VERSION ""

NS_ :

BS_:

BU_:
VAL_TABLE_ RadarCfg_OutputType_Valid 1 "valid " 0 "invalid " ;

BO_ 768 VehInfo1: 8 Vector__XXX
 SG_ YawRate_V : 11|1@0+ (1,0) [0|1] "" Vector__XXX
 SG_ YawRate : 23|16@0+ (0.1,-100) [-100|100] "deg/s" Vector__XXX
 SG_ VehSpeed_V : 7|1@0+ (1,0) [0|1] "" Vector__XXX
 SG_ VehSpeed : 6|11@0+ (0.125,0) [0|0] "kph" Vector__XXX

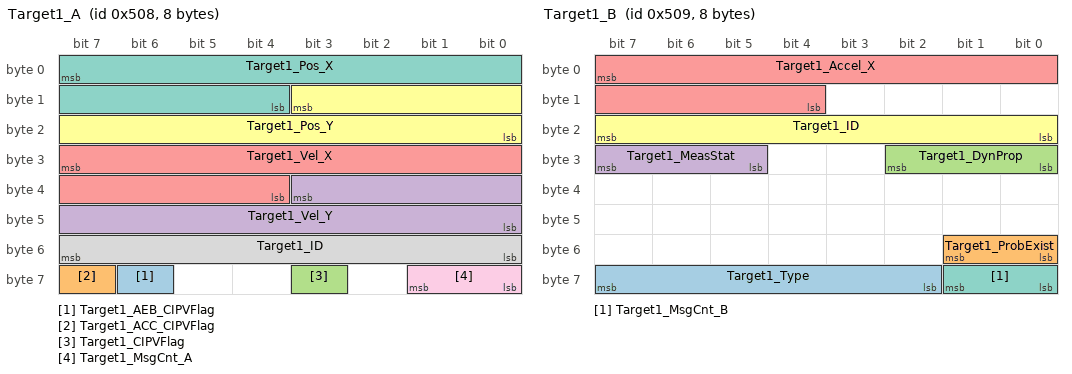
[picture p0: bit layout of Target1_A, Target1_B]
BO_ 1288 Target1_A: 8 Vector__XXX
 SG_ Target1_AEB_CIPVFlag : 62|1@0+ (1,0) [0|1] "" Vector__XXX
 SG_ Target1_ACC_CIPVFlag : 63|1@0+ (1,0) [0|1] "" Vector__XXX
 SG_ Target1_CIPVFlag : 59|1@0+ (1,0) [0|1] "" Vector__XXX
 SG_ Target1_Vel_Y : 35|12@0+ (0.05,-102) [-102|102] "m/s" Vector__XXX
 SG_ Target1_Vel_X : 31|12@0+ (0.05,-102) [-102|102] "m/s" Vector__XXX
 SG_ Target1_Pos_Y : 11|12@0+ (0.125,-128) [-128|127] "m" Vector__XXX
 SG_ Target1_Pos_X : 7|12@0+ (0.125,0) [0|255] "m" Vector__XXX
 SG_ Target1_ID : 55|8@0+ (1,0) [0|255] "" Vector__XXX
 SG_ Target1_MsgCnt_A : 57|2@0+ (1,0) [0|3] "" Vector__XXX

BO_ 1289 Target1_B: 8 Vector__XXX
 SG_ Target1_Type : 63|6@0+ (1,0) [0|4] "" Vector__XXX
 SG_ Target1_ProbExist : 49|2@0+ (1,0) [0|3] "" Vector__XXX
 SG_ Target1_DynProp : 26|3@0+ (1,0) [0|6] "" Vector__XXX
 SG_ Target1_MeasStat : 31|3@0+ (1,0) [0|4] "" Vector__XXX
 SG_ Target1_Accel_X : 7|12@0+ (0.04,-40) [-40|40] "m/s2" Vector__XXX
 SG_ Target1_ID : 23|8@0+ (1,0) [0|255] "" Vector__XXX
 SG_ Target1_MsgCnt_B : 57|2@0+ (1,0) [0|3] "" Vector__XXX

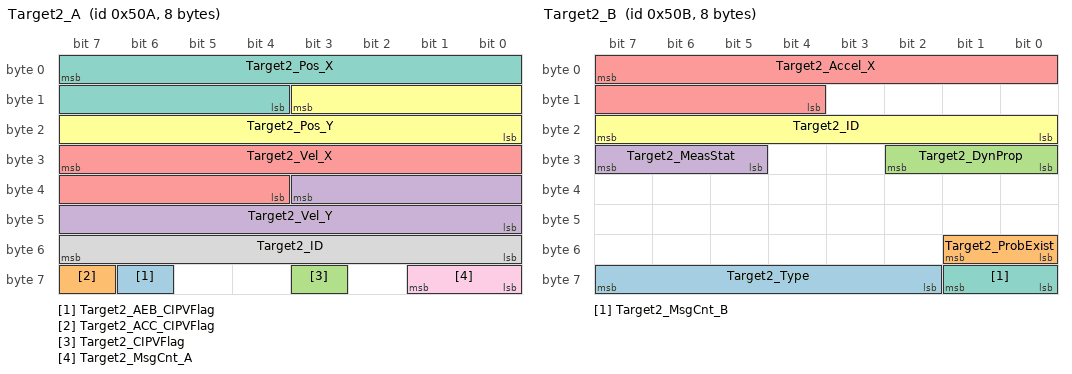
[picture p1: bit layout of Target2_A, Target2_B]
BO_ 1290 Target2_A: 8 Vector__XXX
 SG_ Target2_AEB_CIPVFlag : 62|1@0+ (1,0) [0|1] "" Vector__XXX
 SG_ Target2_ACC_CIPVFlag : 63|1@0+ (1,0) [0|1] "" Vector__XXX
 SG_ Target2_CIPVFlag : 59|1@0+ (1,0) [0|1] "" Vector__XXX
 SG_ Target2_Vel_Y : 35|12@0+ (0.05,-102) [-102|102] "m/s" Vector__XXX
 SG_ Target2_Vel_X : 31|12@0+ (0.05,-102) [-102|102] "m/s" Vector__XXX
 SG_ Target2_Pos_Y : 11|12@0+ (0.125,-128) [-128|127] "m" Vector__XXX
 SG_ Target2_Pos_X : 7|12@0+ (0.125,0) [0|255] "m" Vector__XXX
 SG_ Target2_ID : 55|8@0+ (1,0) [0|255] "" Vector__XXX
 SG_ Target2_MsgCnt_A : 57|2@0+ (1,0) [0|3] "" Vector__XXX

BO_ 1291 Target2_B: 8 Vector__XXX
 SG_ Target2_Type : 63|6@0+ (1,0) [0|4] "" Vector__XXX
 SG_ Target2_ProbExist : 49|2@0+ (1,0) [0|3] "" Vector__XXX
 SG_ Target2_DynProp : 26|3@0+ (1,0) [0|6] "" Vector__XXX
 SG_ Target2_MeasStat : 31|3@0+ (1,0) [0|4] "" Vector__XXX
 SG_ Target2_Accel_X : 7|12@0+ (0.04,-40) [-40|40] "m/s2" Vector__XXX
 SG_ Target2_ID : 23|8@0+ (1,0) [0|255] "" Vector__XXX
 SG_ Target2_MsgCnt_B : 57|2@0+ (1,0) [0|3] "" Vector__XXX

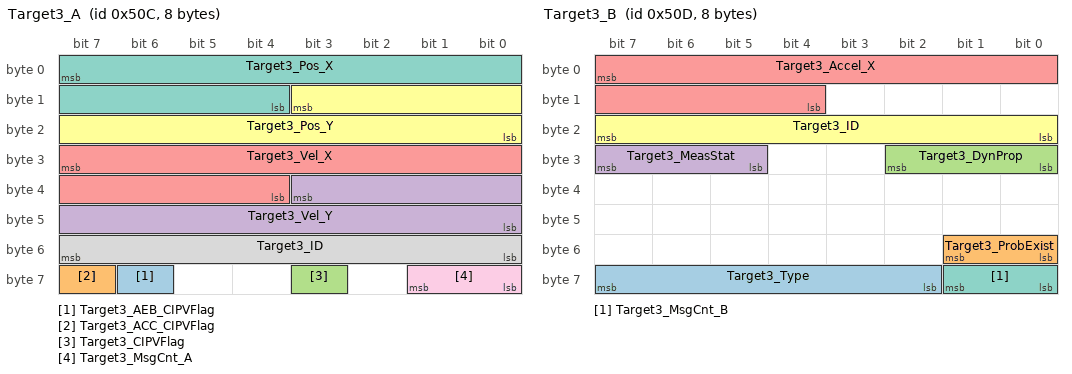
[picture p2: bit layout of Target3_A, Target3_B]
BO_ 1292 Target3_A: 8 Vector__XXX
 SG_ Target3_AEB_CIPVFlag : 62|1@0+ (1,0) [0|1] "" Vector__XXX
 SG_ Target3_ACC_CIPVFlag : 63|1@0+ (1,0) [0|1] "" Vector__XXX
 SG_ Target3_CIPVFlag : 59|1@0+ (1,0) [0|1] "" Vector__XXX
 SG_ Target3_Vel_Y : 35|12@0+ (0.05,-102) [-102|102] "m/s" Vector__XXX
 SG_ Target3_Vel_X : 31|12@0+ (0.05,-102) [-102|102] "m/s" Vector__XXX
 SG_ Target3_Pos_Y : 11|12@0+ (0.125,-128) [-128|127] "m" Vector__XXX
 SG_ Target3_Pos_X : 7|12@0+ (0.125,0) [0|255] "m" Vector__XXX
 SG_ Target3_ID : 55|8@0+ (1,0) [0|255] "" Vector__XXX
 SG_ Target3_MsgCnt_A : 57|2@0+ (1,0) [0|3] "" Vector__XXX

BO_ 1293 Target3_B: 8 Vector__XXX
 SG_ Target3_Type : 63|6@0+ (1,0) [0|4] "" Vector__XXX
 SG_ Target3_ProbExist : 49|2@0+ (1,0) [0|3] "" Vector__XXX
 SG_ Target3_DynProp : 26|3@0+ (1,0) [0|6] "" Vector__XXX
 SG_ Target3_MeasStat : 31|3@0+ (1,0) [0|4] "" Vector__XXX
 SG_ Target3_Accel_X : 7|12@0+ (0.04,-40) [-40|40] "m/s2" Vector__XXX
 SG_ Target3_ID : 23|8@0+ (1,0) [0|255] "" Vector__XXX
 SG_ Target3_MsgCnt_B : 57|2@0+ (1,0) [0|3] "" Vector__XXX

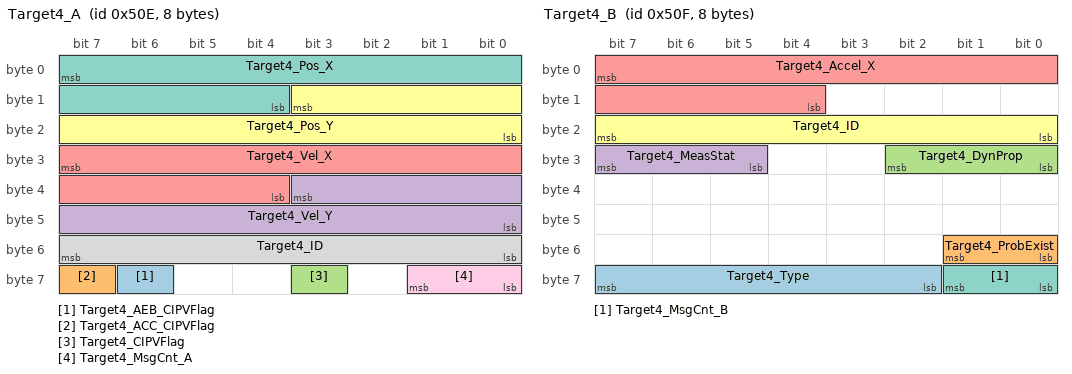
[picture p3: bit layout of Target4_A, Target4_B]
BO_ 1294 Target4_A: 8 Vector__XXX
 SG_ Target4_AEB_CIPVFlag : 62|1@0+ (1,0) [0|1] "" Vector__XXX
 SG_ Target4_ACC_CIPVFlag : 63|1@0+ (1,0) [0|1] "" Vector__XXX
 SG_ Target4_CIPVFlag : 59|1@0+ (1,0) [0|1] "" Vector__XXX
 SG_ Target4_Vel_Y : 35|12@0+ (0.05,-102) [-102|102] "m/s" Vector__XXX
 SG_ Target4_Vel_X : 31|12@0+ (0.05,-102) [-102|102] "m/s" Vector__XXX
 SG_ Target4_Pos_Y : 11|12@0+ (0.125,-128) [-128|127] "m" Vector__XXX
 SG_ Target4_Pos_X : 7|12@0+ (0.125,0) [0|255] "m" Vector__XXX
 SG_ Target4_ID : 55|8@0+ (1,0) [0|255] "" Vector__XXX
 SG_ Target4_MsgCnt_A : 57|2@0+ (1,0) [0|3] "" Vector__XXX

BO_ 1295 Target4_B: 8 Vector__XXX
 SG_ Target4_Type : 63|6@0+ (1,0) [0|4] "" Vector__XXX
 SG_ Target4_ProbExist : 49|2@0+ (1,0) [0|3] "" Vector__XXX
 SG_ Target4_DynProp : 26|3@0+ (1,0) [0|6] "" Vector__XXX
 SG_ Target4_MeasStat : 31|3@0+ (1,0) [0|4] "" Vector__XXX
 SG_ Target4_Accel_X : 7|12@0+ (0.04,-40) [-40|40] "m/s2" Vector__XXX
 SG_ Target4_ID : 23|8@0+ (1,0) [0|255] "" Vector__XXX
 SG_ Target4_MsgCnt_B : 57|2@0+ (1,0) [0|3] "" Vector__XXX

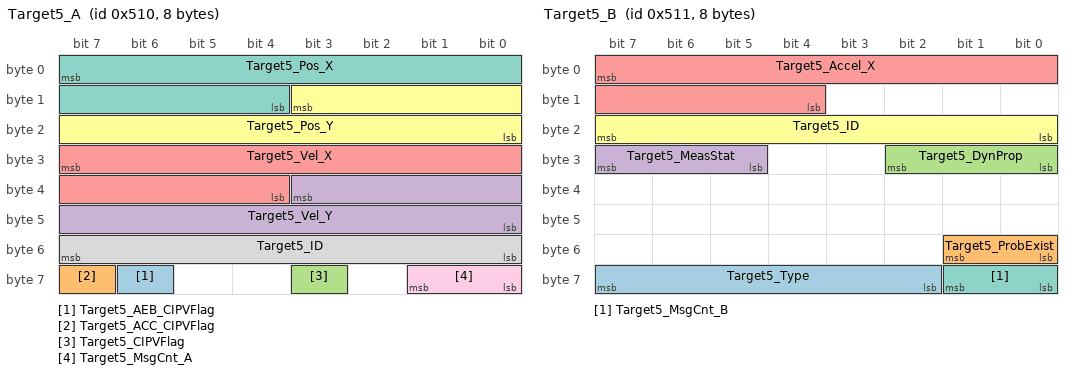
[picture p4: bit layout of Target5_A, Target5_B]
BO_ 1296 Target5_A: 8 Vector__XXX
 SG_ Target5_AEB_CIPVFlag : 62|1@0+ (1,0) [0|1] "" Vector__XXX
 SG_ Target5_ACC_CIPVFlag : 63|1@0+ (1,0) [0|1] "" Vector__XXX
 SG_ Target5_CIPVFlag : 59|1@0+ (1,0) [0|1] "" Vector__XXX
 SG_ Target5_Vel_Y : 35|12@0+ (0.05,-102) [-102|102] "m/s" Vector__XXX
 SG_ Target5_Vel_X : 31|12@0+ (0.05,-102) [-102|102] "m/s" Vector__XXX
 SG_ Target5_Pos_Y : 11|12@0+ (0.125,-128) [-128|127] "m" Vector__XXX
 SG_ Target5_Pos_X : 7|12@0+ (0.125,0) [0|255] "m" Vector__XXX
 SG_ Target5_ID : 55|8@0+ (1,0) [0|255] "" Vector__XXX
 SG_ Target5_MsgCnt_A : 57|2@0+ (1,0) [0|3] "" Vector__XXX

BO_ 1297 Target5_B: 8 Vector__XXX
 SG_ Target5_Type : 63|6@0+ (1,0) [0|4] "" Vector__XXX
 SG_ Target5_ProbExist : 49|2@0+ (1,0) [0|3] "" Vector__XXX
 SG_ Target5_DynProp : 26|3@0+ (1,0) [0|6] "" Vector__XXX
 SG_ Target5_MeasStat : 31|3@0+ (1,0) [0|4] "" Vector__XXX
 SG_ Target5_Accel_X : 7|12@0+ (0.04,-40) [-40|40] "m/s2" Vector__XXX
 SG_ Target5_ID : 23|8@0+ (1,0) [0|255] "" Vector__XXX
 SG_ Target5_MsgCnt_B : 57|2@0+ (1,0) [0|3] "" Vector__XXX

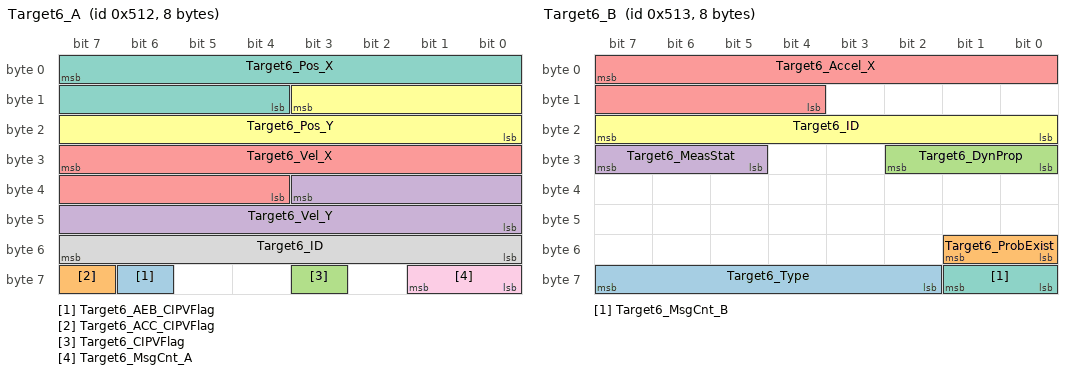
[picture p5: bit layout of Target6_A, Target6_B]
BO_ 1298 Target6_A: 8 Vector__XXX
 SG_ Target6_AEB_CIPVFlag : 62|1@0+ (1,0) [0|1] "" Vector__XXX
 SG_ Target6_ACC_CIPVFlag : 63|1@0+ (1,0) [0|1] "" Vector__XXX
 SG_ Target6_CIPVFlag : 59|1@0+ (1,0) [0|1] "" Vector__XXX
 SG_ Target6_Vel_Y : 35|12@0+ (0.05,-102) [-102|102] "m/s" Vector__XXX
 SG_ Target6_Vel_X : 31|12@0+ (0.05,-102) [-102|102] "m/s" Vector__XXX
 SG_ Target6_Pos_Y : 11|12@0+ (0.125,-128) [-128|127] "m" Vector__XXX
 SG_ Target6_Pos_X : 7|12@0+ (0.125,0) [0|255] "m" Vector__XXX
 SG_ Target6_ID : 55|8@0+ (1,0) [0|255] "" Vector__XXX
 SG_ Target6_MsgCnt_A : 57|2@0+ (1,0) [0|3] "" Vector__XXX

BO_ 1299 Target6_B: 8 Vector__XXX
 SG_ Target6_Type : 63|6@0+ (1,0) [0|4] "" Vector__XXX
 SG_ Target6_ProbExist : 49|2@0+ (1,0) [0|3] "" Vector__XXX
 SG_ Target6_DynProp : 26|3@0+ (1,0) [0|6] "" Vector__XXX
 SG_ Target6_MeasStat : 31|3@0+ (1,0) [0|4] "" Vector__XXX
 SG_ Target6_Accel_X : 7|12@0+ (0.04,-40) [-40|40] "m/s2" Vector__XXX
 SG_ Target6_ID : 23|8@0+ (1,0) [0|255] "" Vector__XXX
 SG_ Target6_MsgCnt_B : 57|2@0+ (1,0) [0|3] "" Vector__XXX

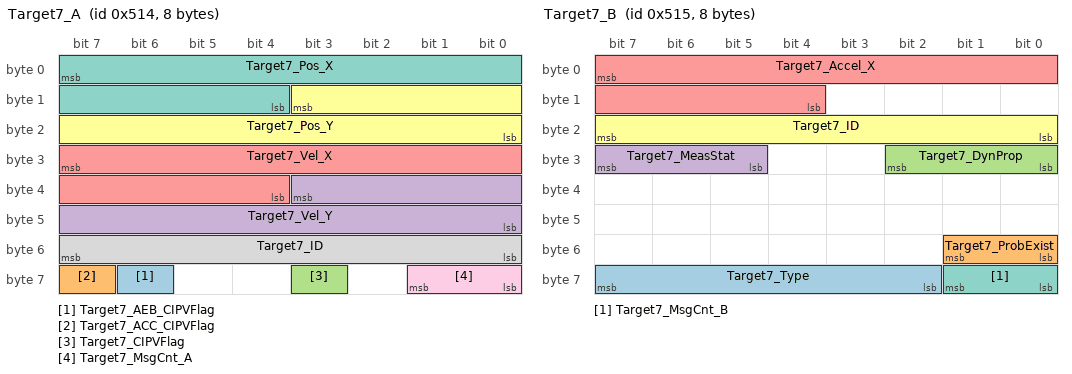
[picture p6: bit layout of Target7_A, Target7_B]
BO_ 1300 Target7_A: 8 Vector__XXX
 SG_ Target7_AEB_CIPVFlag : 62|1@0+ (1,0) [0|1] "" Vector__XXX
 SG_ Target7_ACC_CIPVFlag : 63|1@0+ (1,0) [0|1] "" Vector__XXX
 SG_ Target7_CIPVFlag : 59|1@0+ (1,0) [0|1] "" Vector__XXX
 SG_ Target7_Vel_Y : 35|12@0+ (0.05,-102) [-102|102] "m/s" Vector__XXX
 SG_ Target7_Vel_X : 31|12@0+ (0.05,-102) [-102|102] "m/s" Vector__XXX
 SG_ Target7_Pos_Y : 11|12@0+ (0.125,-128) [-128|127] "m" Vector__XXX
 SG_ Target7_Pos_X : 7|12@0+ (0.125,0) [0|255] "m" Vector__XXX
 SG_ Target7_ID : 55|8@0+ (1,0) [0|255] "" Vector__XXX
 SG_ Target7_MsgCnt_A : 57|2@0+ (1,0) [0|3] "" Vector__XXX

BO_ 1301 Target7_B: 8 Vector__XXX
 SG_ Target7_Type : 63|6@0+ (1,0) [0|4] "" Vector__XXX
 SG_ Target7_ProbExist : 49|2@0+ (1,0) [0|3] "" Vector__XXX
 SG_ Target7_DynProp : 26|3@0+ (1,0) [0|6] "" Vector__XXX
 SG_ Target7_MeasStat : 31|3@0+ (1,0) [0|4] "" Vector__XXX
 SG_ Target7_Accel_X : 7|12@0+ (0.04,-40) [-40|40] "m/s2" Vector__XXX
 SG_ Target7_ID : 23|8@0+ (1,0) [0|255] "" Vector__XXX
 SG_ Target7_MsgCnt_B : 57|2@0+ (1,0) [0|3] "" Vector__XXX

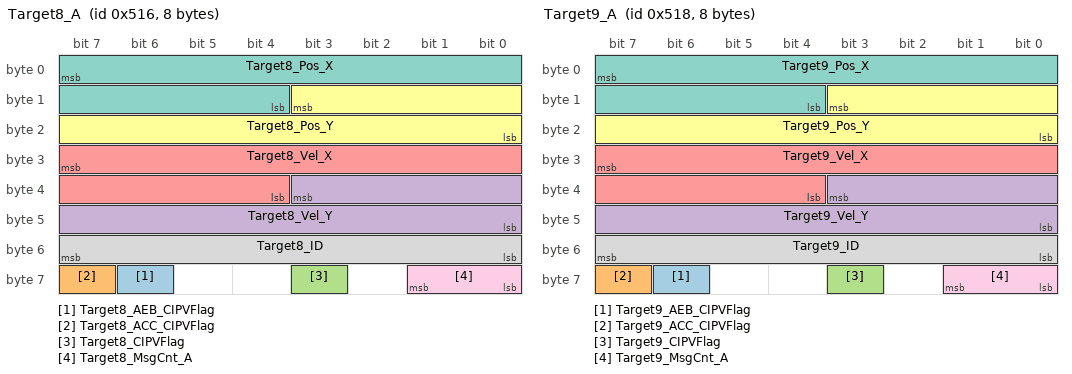
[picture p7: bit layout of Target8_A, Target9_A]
BO_ 1302 Target8_A: 8 Vector__XXX
 SG_ Target8_AEB_CIPVFlag : 62|1@0+ (1,0) [0|1] "" Vector__XXX
 SG_ Target8_ACC_CIPVFlag : 63|1@0+ (1,0) [0|1] "" Vector__XXX
 SG_ Target8_CIPVFlag : 59|1@0+ (1,0) [0|1] "" Vector__XXX
 SG_ Target8_Vel_Y : 35|12@0+ (0.05,-102) [-102|102] "m/s" Vector__XXX
 SG_ Target8_Vel_X : 31|12@0+ (0.05,-102) [-102|102] "m/s" Vector__XXX
 SG_ Target8_Pos_Y : 11|12@0+ (0.125,-128) [-128|127] "m" Vector__XXX
 SG_ Target8_Pos_X : 7|12@0+ (0.125,0) [0|255] "m" Vector__XXX
 SG_ Target8_ID : 55|8@0+ (1,0) [0|255] "" Vector__XXX
 SG_ Target8_MsgCnt_A : 57|2@0+ (1,0) [0|3] "" Vector__XXX

BO_ 1303 Target8_B: 8 Vector__XXX
 SG_ Target8_Type : 63|6@0+ (1,0) [0|4] "" Vector__XXX
 SG_ Target8_ProbExist : 49|2@0+ (1,0) [0|3] "" Vector__XXX
 SG_ Target8_DynProp : 26|3@0+ (1,0) [0|6] "" Vector__XXX
 SG_ Target8_MeasStat : 31|3@0+ (1,0) [0|4] "" Vector__XXX
 SG_ Target8_Accel_X : 7|12@0+ (0.04,-40) [-40|40] "m/s2" Vector__XXX
 SG_ Target8_ID : 23|8@0+ (1,0) [0|255] "" Vector__XXX
 SG_ Target8_MsgCnt_B : 57|2@0+ (1,0) [0|3] "" Vector__XXX

BO_ 1304 Target9_A: 8 Vector__XXX
 SG_ Target9_AEB_CIPVFlag : 62|1@0+ (1,0) [0|1] "" Vector__XXX
 SG_ Target9_ACC_CIPVFlag : 63|1@0+ (1,0) [0|1] "" Vector__XXX
 SG_ Target9_CIPVFlag : 59|1@0+ (1,0) [0|1] "" Vector__XXX
 SG_ Target9_Vel_Y : 35|12@0+ (0.05,-102) [-102|102] "m/s" Vector__XXX
 SG_ Target9_Vel_X : 31|12@0+ (0.05,-102) [-102|102] "m/s" Vector__XXX
 SG_ Target9_Pos_Y : 11|12@0+ (0.125,-128) [-128|127] "m" Vector__XXX
 SG_ Target9_Pos_X : 7|12@0+ (0.125,0) [0|255] "m" Vector__XXX
 SG_ Target9_ID : 55|8@0+ (1,0) [0|255] "" Vector__XXX
 SG_ Target9_MsgCnt_A : 57|2@0+ (1,0) [0|3] "" Vector__XXX

BO_ 1305 Target9_B: 8 Vector__XXX
 SG_ Target9_Type : 63|6@0+ (1,0) [0|4] "" Vector__XXX
 SG_ Target9_ProbExist : 49|2@0+ (1,0) [0|3] "" Vector__XXX
 SG_ Target9_DynProp : 26|3@0+ (1,0) [0|6] "" Vector__XXX
 SG_ Target9_MeasStat : 31|3@0+ (1,0) [0|4] "" Vector__XXX
 SG_ Target9_Accel_X : 7|12@0+ (0.04,-40) [-40|40] "m/s2" Vector__XXX
 SG_ Target9_ID : 23|8@0+ (1,0) [0|255] "" Vector__XXX
 SG_ Target9_MsgCnt_B : 57|2@0+ (1,0) [0|3] "" Vector__XXX

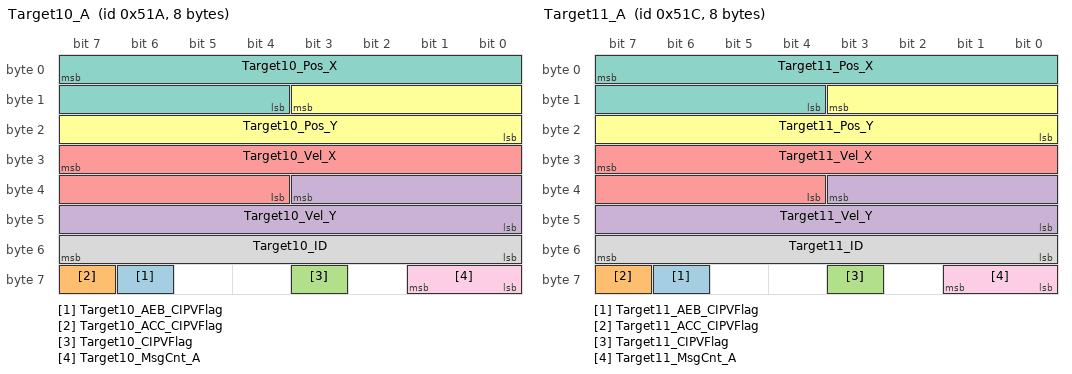
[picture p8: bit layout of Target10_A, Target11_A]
BO_ 1306 Target10_A: 8 Vector__XXX
 SG_ Target10_AEB_CIPVFlag : 62|1@0+ (1,0) [0|1] "" Vector__XXX
 SG_ Target10_ACC_CIPVFlag : 63|1@0+ (1,0) [0|1] "" Vector__XXX
 SG_ Target10_CIPVFlag : 59|1@0+ (1,0) [0|1] "" Vector__XXX
 SG_ Target10_Vel_Y : 35|12@0+ (0.05,-102) [-102|102] "m/s" Vector__XXX
 SG_ Target10_Vel_X : 31|12@0+ (0.05,-102) [-102|102] "m/s" Vector__XXX
 SG_ Target10_Pos_Y : 11|12@0+ (0.125,-128) [-128|127] "m" Vector__XXX
 SG_ Target10_Pos_X : 7|12@0+ (0.125,0) [0|255] "m" Vector__XXX
 SG_ Target10_ID : 55|8@0+ (1,0) [0|255] "" Vector__XXX
 SG_ Target10_MsgCnt_A : 57|2@0+ (1,0) [0|3] "" Vector__XXX

BO_ 1307 Target10_B: 8 Vector__XXX
 SG_ Target10_Type : 63|6@0+ (1,0) [0|4] "" Vector__XXX
 SG_ Target10_ProbExist : 49|2@0+ (1,0) [0|3] "" Vector__XXX
 SG_ Target10_DynProp : 26|3@0+ (1,0) [0|6] "" Vector__XXX
 SG_ Target10_MeasStat : 31|3@0+ (1,0) [0|4] "" Vector__XXX
 SG_ Target10_Accel_X : 7|12@0+ (0.04,-40) [-40|40] "m/s2" Vector__XXX
 SG_ Target10_ID : 23|8@0+ (1,0) [0|255] "" Vector__XXX
 SG_ Target10_MsgCnt_B : 57|2@0+ (1,0) [0|3] "" Vector__XXX

BO_ 1308 Target11_A: 8 Vector__XXX
 SG_ Target11_AEB_CIPVFlag : 62|1@0+ (1,0) [0|1] "" Vector__XXX
 SG_ Target11_ACC_CIPVFlag : 63|1@0+ (1,0) [0|1] "" Vector__XXX
 SG_ Target11_CIPVFlag : 59|1@0+ (1,0) [0|1] "" Vector__XXX
 SG_ Target11_Vel_Y : 35|12@0+ (0.05,-102) [-102|102] "m/s" Vector__XXX
 SG_ Target11_Vel_X : 31|12@0+ (0.05,-102) [-102|102] "m/s" Vector__XXX
 SG_ Target11_Pos_Y : 11|12@0+ (0.125,-128) [-128|127] "m" Vector__XXX
 SG_ Target11_Pos_X : 7|12@0+ (0.125,0) [0|255] "m" Vector__XXX
 SG_ Target11_ID : 55|8@0+ (1,0) [0|255] "" Vector__XXX
 SG_ Target11_MsgCnt_A : 57|2@0+ (1,0) [0|3] "" Vector__XXX

BO_ 1309 Target11_B: 8 Vector__XXX
 SG_ Target11_Type : 63|6@0+ (1,0) [0|4] "" Vector__XXX
 SG_ Target11_ProbExist : 49|2@0+ (1,0) [0|3] "" Vector__XXX
 SG_ Target11_DynProp : 26|3@0+ (1,0) [0|6] "" Vector__XXX
 SG_ Target11_MeasStat : 31|3@0+ (1,0) [0|4] "" Vector__XXX
 SG_ Target11_Accel_X : 7|12@0+ (0.04,-40) [-40|40] "m/s2" Vector__XXX
 SG_ Target11_ID : 23|8@0+ (1,0) [0|255] "" Vector__XXX
 SG_ Target11_MsgCnt_B : 57|2@0+ (1,0) [0|3] "" Vector__XXX

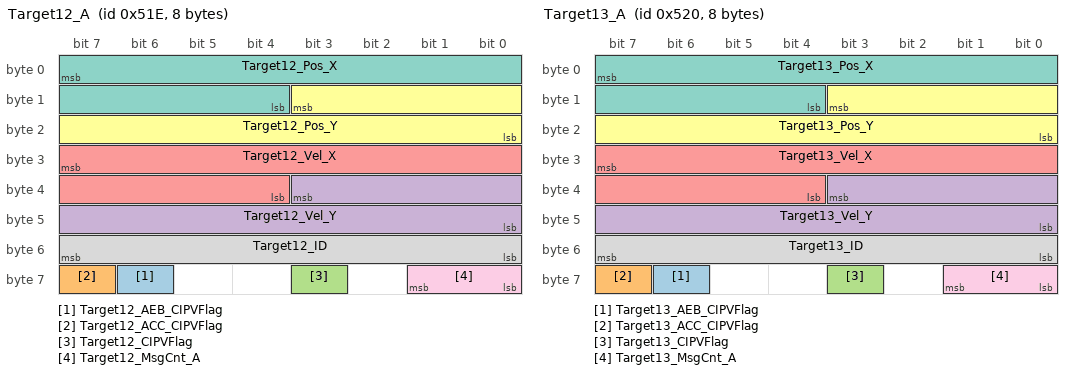
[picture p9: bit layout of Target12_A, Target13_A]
BO_ 1310 Target12_A: 8 Vector__XXX
 SG_ Target12_AEB_CIPVFlag : 62|1@0+ (1,0) [0|1] "" Vector__XXX
 SG_ Target12_ACC_CIPVFlag : 63|1@0+ (1,0) [0|1] "" Vector__XXX
 SG_ Target12_CIPVFlag : 59|1@0+ (1,0) [0|1] "" Vector__XXX
 SG_ Target12_Vel_Y : 35|12@0+ (0.05,-102) [-102|102] "m/s" Vector__XXX
 SG_ Target12_Vel_X : 31|12@0+ (0.05,-102) [-102|102] "m/s" Vector__XXX
 SG_ Target12_Pos_Y : 11|12@0+ (0.125,-128) [-128|127] "m" Vector__XXX
 SG_ Target12_Pos_X : 7|12@0+ (0.125,0) [0|255] "m" Vector__XXX
 SG_ Target12_ID : 55|8@0+ (1,0) [0|255] "" Vector__XXX
 SG_ Target12_MsgCnt_A : 57|2@0+ (1,0) [0|3] "" Vector__XXX

BO_ 1311 Target12_B: 8 Vector__XXX
 SG_ Target12_Type : 63|6@0+ (1,0) [0|4] "" Vector__XXX
 SG_ Target12_ProbExist : 49|2@0+ (1,0) [0|3] "" Vector__XXX
 SG_ Target12_DynProp : 26|3@0+ (1,0) [0|6] "" Vector__XXX
 SG_ Target12_MeasStat : 31|3@0+ (1,0) [0|4] "" Vector__XXX
 SG_ Target12_Accel_X : 7|12@0+ (0.04,-40) [-40|40] "m/s2" Vector__XXX
 SG_ Target12_ID : 23|8@0+ (1,0) [0|255] "" Vector__XXX
 SG_ Target12_MsgCnt_B : 57|2@0+ (1,0) [0|3] "" Vector__XXX

BO_ 1312 Target13_A: 8 Vector__XXX
 SG_ Target13_AEB_CIPVFlag : 62|1@0+ (1,0) [0|1] "" Vector__XXX
 SG_ Target13_ACC_CIPVFlag : 63|1@0+ (1,0) [0|1] "" Vector__XXX
 SG_ Target13_CIPVFlag : 59|1@0+ (1,0) [0|1] "" Vector__XXX
 SG_ Target13_Vel_Y : 35|12@0+ (0.05,-102) [-102|102] "m/s" Vector__XXX
 SG_ Target13_Vel_X : 31|12@0+ (0.05,-102) [-102|102] "m/s" Vector__XXX
 SG_ Target13_Pos_Y : 11|12@0+ (0.125,-128) [-128|127] "m" Vector__XXX
 SG_ Target13_Pos_X : 7|12@0+ (0.125,0) [0|255] "m" Vector__XXX
 SG_ Target13_ID : 55|8@0+ (1,0) [0|255] "" Vector__XXX
 SG_ Target13_MsgCnt_A : 57|2@0+ (1,0) [0|3] "" Vector__XXX

BO_ 1313 Target13_B: 8 Vector__XXX
 SG_ Target13_Type : 63|6@0+ (1,0) [0|4] "" Vector__XXX
 SG_ Target13_ProbExist : 49|2@0+ (1,0) [0|3] "" Vector__XXX
 SG_ Target13_DynProp : 26|3@0+ (1,0) [0|6] "" Vector__XXX
 SG_ Target13_MeasStat : 31|3@0+ (1,0) [0|4] "" Vector__XXX
 SG_ Target13_Accel_X : 7|12@0+ (0.04,-40) [-40|40] "m/s2" Vector__XXX
 SG_ Target13_ID : 23|8@0+ (1,0) [0|255] "" Vector__XXX
 SG_ Target13_MsgCnt_B : 57|2@0+ (1,0) [0|3] "" Vector__XXX

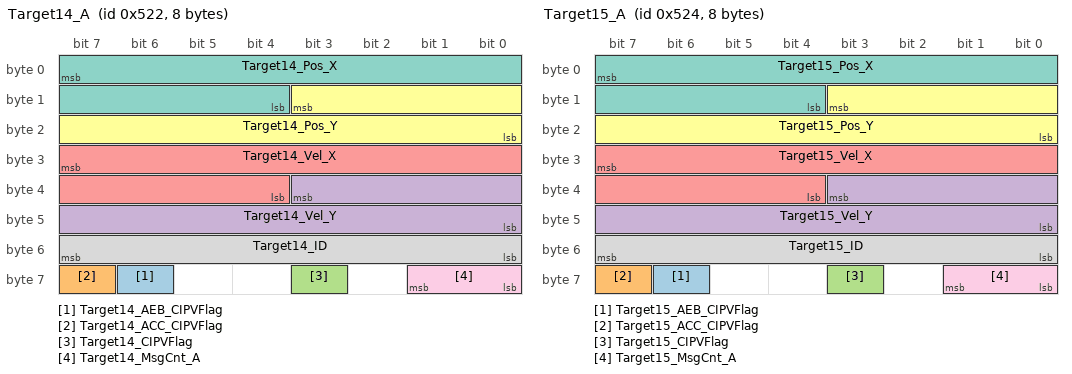
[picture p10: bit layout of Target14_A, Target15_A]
BO_ 1314 Target14_A: 8 Vector__XXX
 SG_ Target14_AEB_CIPVFlag : 62|1@0+ (1,0) [0|1] "" Vector__XXX
 SG_ Target14_ACC_CIPVFlag : 63|1@0+ (1,0) [0|1] "" Vector__XXX
 SG_ Target14_CIPVFlag : 59|1@0+ (1,0) [0|1] "" Vector__XXX
 SG_ Target14_Vel_Y : 35|12@0+ (0.05,-102) [-102|102] "m/s" Vector__XXX
 SG_ Target14_Vel_X : 31|12@0+ (0.05,-102) [-102|102] "m/s" Vector__XXX
 SG_ Target14_Pos_Y : 11|12@0+ (0.125,-128) [-128|127] "m" Vector__XXX
 SG_ Target14_Pos_X : 7|12@0+ (0.125,0) [0|255] "m" Vector__XXX
 SG_ Target14_ID : 55|8@0+ (1,0) [0|255] "" Vector__XXX
 SG_ Target14_MsgCnt_A : 57|2@0+ (1,0) [0|3] "" Vector__XXX

BO_ 1315 Target14_B: 8 Vector__XXX
 SG_ Target14_Type : 63|6@0+ (1,0) [0|4] "" Vector__XXX
 SG_ Target14_ProbExist : 49|2@0+ (1,0) [0|3] "" Vector__XXX
 SG_ Target14_DynProp : 26|3@0+ (1,0) [0|6] "" Vector__XXX
 SG_ Target14_MeasStat : 31|3@0+ (1,0) [0|4] "" Vector__XXX
 SG_ Target14_Accel_X : 7|12@0+ (0.04,-40) [-40|40] "m/s2" Vector__XXX
 SG_ Target14_ID : 23|8@0+ (1,0) [0|255] "" Vector__XXX
 SG_ Target14_MsgCnt_B : 57|2@0+ (1,0) [0|3] "" Vector__XXX

BO_ 1316 Target15_A: 8 Vector__XXX
 SG_ Target15_AEB_CIPVFlag : 62|1@0+ (1,0) [0|1] "" Vector__XXX
 SG_ Target15_ACC_CIPVFlag : 63|1@0+ (1,0) [0|1] "" Vector__XXX
 SG_ Target15_CIPVFlag : 59|1@0+ (1,0) [0|1] "" Vector__XXX
 SG_ Target15_Vel_Y : 35|12@0+ (0.05,-102) [-102|102] "m/s" Vector__XXX
 SG_ Target15_Vel_X : 31|12@0+ (0.05,-102) [-102|102] "m/s" Vector__XXX
 SG_ Target15_Pos_Y : 11|12@0+ (0.125,-128) [-128|127] "m" Vector__XXX
 SG_ Target15_Pos_X : 7|12@0+ (0.125,0) [0|255] "m" Vector__XXX
 SG_ Target15_ID : 55|8@0+ (1,0) [0|255] "" Vector__XXX
 SG_ Target15_MsgCnt_A : 57|2@0+ (1,0) [0|3] "" Vector__XXX

BO_ 1317 Target15_B: 8 Vector__XXX
 SG_ Target15_Type : 63|6@0+ (1,0) [0|4] "" Vector__XXX
 SG_ Target15_ProbExist : 49|2@0+ (1,0) [0|3] "" Vector__XXX
 SG_ Target15_DynProp : 26|3@0+ (1,0) [0|6] "" Vector__XXX
 SG_ Target15_MeasStat : 31|3@0+ (1,0) [0|4] "" Vector__XXX
 SG_ Target15_Accel_X : 7|12@0+ (0.04,-40) [-40|40] "m/s2" Vector__XXX
 SG_ Target15_ID : 23|8@0+ (1,0) [0|255] "" Vector__XXX
 SG_ Target15_MsgCnt_B : 57|2@0+ (1,0) [0|3] "" Vector__XXX

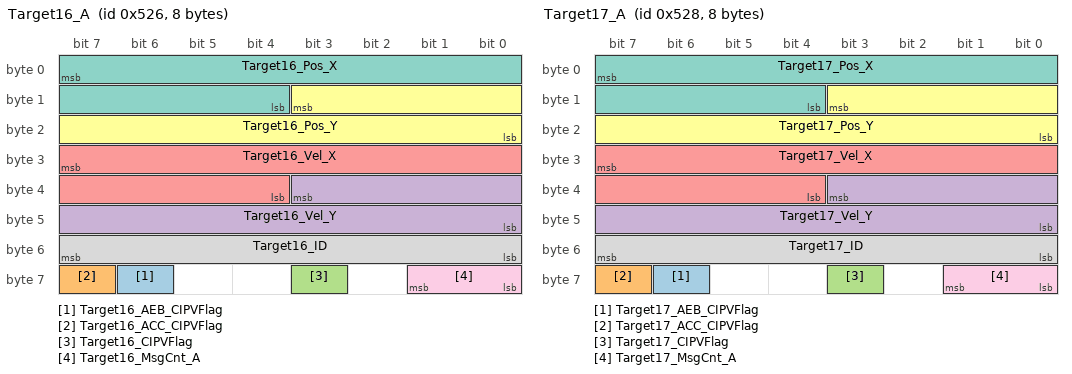
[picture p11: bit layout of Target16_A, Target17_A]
BO_ 1318 Target16_A: 8 Vector__XXX
 SG_ Target16_AEB_CIPVFlag : 62|1@0+ (1,0) [0|1] "" Vector__XXX
 SG_ Target16_ACC_CIPVFlag : 63|1@0+ (1,0) [0|1] "" Vector__XXX
 SG_ Target16_CIPVFlag : 59|1@0+ (1,0) [0|1] "" Vector__XXX
 SG_ Target16_Vel_Y : 35|12@0+ (0.05,-102) [-102|102] "m/s" Vector__XXX
 SG_ Target16_Vel_X : 31|12@0+ (0.05,-102) [-102|102] "m/s" Vector__XXX
 SG_ Target16_Pos_Y : 11|12@0+ (0.125,-128) [-128|127] "m" Vector__XXX
 SG_ Target16_Pos_X : 7|12@0+ (0.125,0) [0|255] "m" Vector__XXX
 SG_ Target16_ID : 55|8@0+ (1,0) [0|255] "" Vector__XXX
 SG_ Target16_MsgCnt_A : 57|2@0+ (1,0) [0|3] "" Vector__XXX

BO_ 1319 Target16_B: 8 Vector__XXX
 SG_ Target16_Type : 63|6@0+ (1,0) [0|4] "" Vector__XXX
 SG_ Target16_ProbExist : 49|2@0+ (1,0) [0|3] "" Vector__XXX
 SG_ Target16_DynProp : 26|3@0+ (1,0) [0|6] "" Vector__XXX
 SG_ Target16_MeasStat : 31|3@0+ (1,0) [0|4] "" Vector__XXX
 SG_ Target16_Accel_X : 7|12@0+ (0.04,-40) [-40|40] "m/s2" Vector__XXX
 SG_ Target16_ID : 23|8@0+ (1,0) [0|255] "" Vector__XXX
 SG_ Target16_MsgCnt_B : 57|2@0+ (1,0) [0|3] "" Vector__XXX

BO_ 1320 Target17_A: 8 Vector__XXX
 SG_ Target17_AEB_CIPVFlag : 62|1@0+ (1,0) [0|1] "" Vector__XXX
 SG_ Target17_ACC_CIPVFlag : 63|1@0+ (1,0) [0|1] "" Vector__XXX
 SG_ Target17_CIPVFlag : 59|1@0+ (1,0) [0|1] "" Vector__XXX
 SG_ Target17_Vel_Y : 35|12@0+ (0.05,-102) [-102|102] "m/s" Vector__XXX
 SG_ Target17_Vel_X : 31|12@0+ (0.05,-102) [-102|102] "m/s" Vector__XXX
 SG_ Target17_Pos_Y : 11|12@0+ (0.125,-128) [-128|127] "m" Vector__XXX
 SG_ Target17_Pos_X : 7|12@0+ (0.125,0) [0|255] "m" Vector__XXX
 SG_ Target17_ID : 55|8@0+ (1,0) [0|255] "" Vector__XXX
 SG_ Target17_MsgCnt_A : 57|2@0+ (1,0) [0|3] "" Vector__XXX

BO_ 1321 Target17_B: 8 Vector__XXX
 SG_ Target17_Type : 63|6@0+ (1,0) [0|4] "" Vector__XXX
 SG_ Target17_ProbExist : 49|2@0+ (1,0) [0|3] "" Vector__XXX
 SG_ Target17_DynProp : 26|3@0+ (1,0) [0|6] "" Vector__XXX
 SG_ Target17_MeasStat : 31|3@0+ (1,0) [0|4] "" Vector__XXX
 SG_ Target17_Accel_X : 7|12@0+ (0.04,-40) [-40|40] "m/s2" Vector__XXX
 SG_ Target17_ID : 23|8@0+ (1,0) [0|255] "" Vector__XXX
 SG_ Target17_MsgCnt_B : 57|2@0+ (1,0) [0|3] "" Vector__XXX

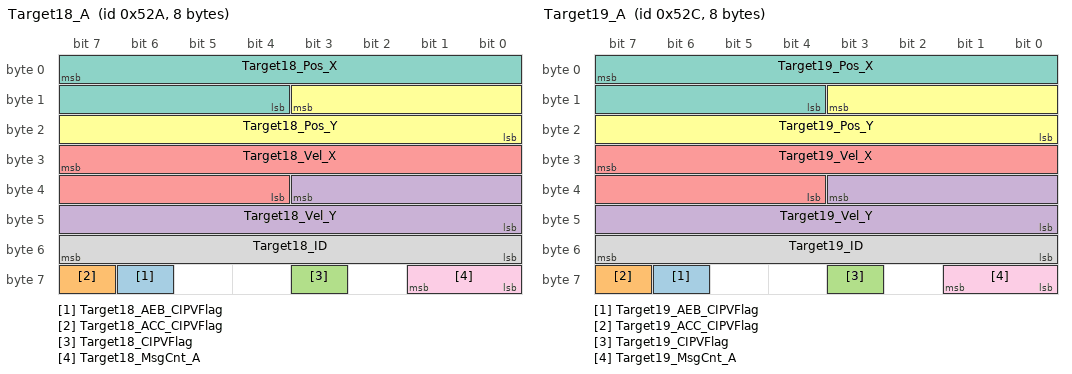
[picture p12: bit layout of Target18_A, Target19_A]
BO_ 1322 Target18_A: 8 Vector__XXX
 SG_ Target18_AEB_CIPVFlag : 62|1@0+ (1,0) [0|1] "" Vector__XXX
 SG_ Target18_ACC_CIPVFlag : 63|1@0+ (1,0) [0|1] "" Vector__XXX
 SG_ Target18_CIPVFlag : 59|1@0+ (1,0) [0|1] "" Vector__XXX
 SG_ Target18_Vel_Y : 35|12@0+ (0.05,-102) [-102|102] "m/s" Vector__XXX
 SG_ Target18_Vel_X : 31|12@0+ (0.05,-102) [-102|102] "m/s" Vector__XXX
 SG_ Target18_Pos_Y : 11|12@0+ (0.125,-128) [-128|127] "m" Vector__XXX
 SG_ Target18_Pos_X : 7|12@0+ (0.125,0) [0|255] "m" Vector__XXX
 SG_ Target18_ID : 55|8@0+ (1,0) [0|255] "" Vector__XXX
 SG_ Target18_MsgCnt_A : 57|2@0+ (1,0) [0|3] "" Vector__XXX

BO_ 1323 Target18_B: 8 Vector__XXX
 SG_ Target18_Type : 63|6@0+ (1,0) [0|4] "" Vector__XXX
 SG_ Target18_ProbExist : 49|2@0+ (1,0) [0|3] "" Vector__XXX
 SG_ Target18_DynProp : 26|3@0+ (1,0) [0|6] "" Vector__XXX
 SG_ Target18_MeasStat : 31|3@0+ (1,0) [0|4] "" Vector__XXX
 SG_ Target18_Accel_X : 7|12@0+ (0.04,-40) [-40|40] "m/s2" Vector__XXX
 SG_ Target18_ID : 23|8@0+ (1,0) [0|255] "" Vector__XXX
 SG_ Target18_MsgCnt_B : 57|2@0+ (1,0) [0|3] "" Vector__XXX

BO_ 1324 Target19_A: 8 Vector__XXX
 SG_ Target19_AEB_CIPVFlag : 62|1@0+ (1,0) [0|1] "" Vector__XXX
 SG_ Target19_ACC_CIPVFlag : 63|1@0+ (1,0) [0|1] "" Vector__XXX
 SG_ Target19_CIPVFlag : 59|1@0+ (1,0) [0|1] "" Vector__XXX
 SG_ Target19_Vel_Y : 35|12@0+ (0.05,-102) [-102|102] "m/s" Vector__XXX
 SG_ Target19_Vel_X : 31|12@0+ (0.05,-102) [-102|102] "m/s" Vector__XXX
 SG_ Target19_Pos_Y : 11|12@0+ (0.125,-128) [-128|127] "m" Vector__XXX
 SG_ Target19_Pos_X : 7|12@0+ (0.125,0) [0|255] "m" Vector__XXX
 SG_ Target19_ID : 55|8@0+ (1,0) [0|255] "" Vector__XXX
 SG_ Target19_MsgCnt_A : 57|2@0+ (1,0) [0|3] "" Vector__XXX

BO_ 1325 Target19_B: 8 Vector__XXX
 SG_ Target19_Type : 63|6@0+ (1,0) [0|4] "" Vector__XXX
 SG_ Target19_ProbExist : 49|2@0+ (1,0) [0|3] "" Vector__XXX
 SG_ Target19_DynProp : 26|3@0+ (1,0) [0|6] "" Vector__XXX
 SG_ Target19_MeasStat : 31|3@0+ (1,0) [0|4] "" Vector__XXX
 SG_ Target19_Accel_X : 7|12@0+ (0.04,-40) [-40|40] "m/s2" Vector__XXX
 SG_ Target19_ID : 23|8@0+ (1,0) [0|255] "" Vector__XXX
 SG_ Target19_MsgCnt_B : 57|2@0+ (1,0) [0|3] "" Vector__XXX

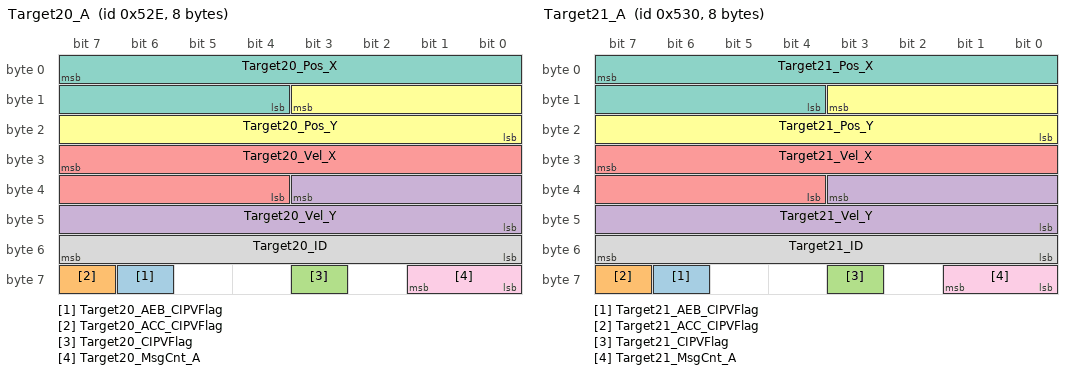
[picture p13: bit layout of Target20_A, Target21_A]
BO_ 1326 Target20_A: 8 Vector__XXX
 SG_ Target20_AEB_CIPVFlag : 62|1@0+ (1,0) [0|1] "" Vector__XXX
 SG_ Target20_ACC_CIPVFlag : 63|1@0+ (1,0) [0|1] "" Vector__XXX
 SG_ Target20_CIPVFlag : 59|1@0+ (1,0) [0|1] "" Vector__XXX
 SG_ Target20_Vel_Y : 35|12@0+ (0.05,-102) [-102|102] "m/s" Vector__XXX
 SG_ Target20_Vel_X : 31|12@0+ (0.05,-102) [-102|102] "m/s" Vector__XXX
 SG_ Target20_Pos_Y : 11|12@0+ (0.125,-128) [-128|127] "m" Vector__XXX
 SG_ Target20_Pos_X : 7|12@0+ (0.125,0) [0|255] "m" Vector__XXX
 SG_ Target20_ID : 55|8@0+ (1,0) [0|255] "" Vector__XXX
 SG_ Target20_MsgCnt_A : 57|2@0+ (1,0) [0|3] "" Vector__XXX

BO_ 1327 Target20_B: 8 Vector__XXX
 SG_ Target20_Type : 63|6@0+ (1,0) [0|4] "" Vector__XXX
 SG_ Target20_ProbExist : 49|2@0+ (1,0) [0|3] "" Vector__XXX
 SG_ Target20_DynProp : 26|3@0+ (1,0) [0|6] "" Vector__XXX
 SG_ Target20_MeasStat : 31|3@0+ (1,0) [0|4] "" Vector__XXX
 SG_ Target20_Accel_X : 7|12@0+ (0.04,-40) [-40|40] "m/s2" Vector__XXX
 SG_ Target20_ID : 23|8@0+ (1,0) [0|255] "" Vector__XXX
 SG_ Target20_MsgCnt_B : 57|2@0+ (1,0) [0|3] "" Vector__XXX

BO_ 1328 Target21_A: 8 Vector__XXX
 SG_ Target21_AEB_CIPVFlag : 62|1@0+ (1,0) [0|1] "" Vector__XXX
 SG_ Target21_ACC_CIPVFlag : 63|1@0+ (1,0) [0|1] "" Vector__XXX
 SG_ Target21_CIPVFlag : 59|1@0+ (1,0) [0|1] "" Vector__XXX
 SG_ Target21_Vel_Y : 35|12@0+ (0.05,-102) [-102|102] "m/s" Vector__XXX
 SG_ Target21_Vel_X : 31|12@0+ (0.05,-102) [-102|102] "m/s" Vector__XXX
 SG_ Target21_Pos_Y : 11|12@0+ (0.125,-128) [-128|127] "m" Vector__XXX
 SG_ Target21_Pos_X : 7|12@0+ (0.125,0) [0|255] "m" Vector__XXX
 SG_ Target21_ID : 55|8@0+ (1,0) [0|255] "" Vector__XXX
 SG_ Target21_MsgCnt_A : 57|2@0+ (1,0) [0|3] "" Vector__XXX

BO_ 1329 Target21_B: 8 Vector__XXX
 SG_ Target21_Type : 63|6@0+ (1,0) [0|4] "" Vector__XXX
 SG_ Target21_ProbExist : 49|2@0+ (1,0) [0|3] "" Vector__XXX
 SG_ Target21_DynProp : 26|3@0+ (1,0) [0|6] "" Vector__XXX
 SG_ Target21_MeasStat : 31|3@0+ (1,0) [0|4] "" Vector__XXX
 SG_ Target21_Accel_X : 7|12@0+ (0.04,-40) [-40|40] "m/s2" Vector__XXX
 SG_ Target21_ID : 23|8@0+ (1,0) [0|255] "" Vector__XXX
 SG_ Target21_MsgCnt_B : 57|2@0+ (1,0) [0|3] "" Vector__XXX

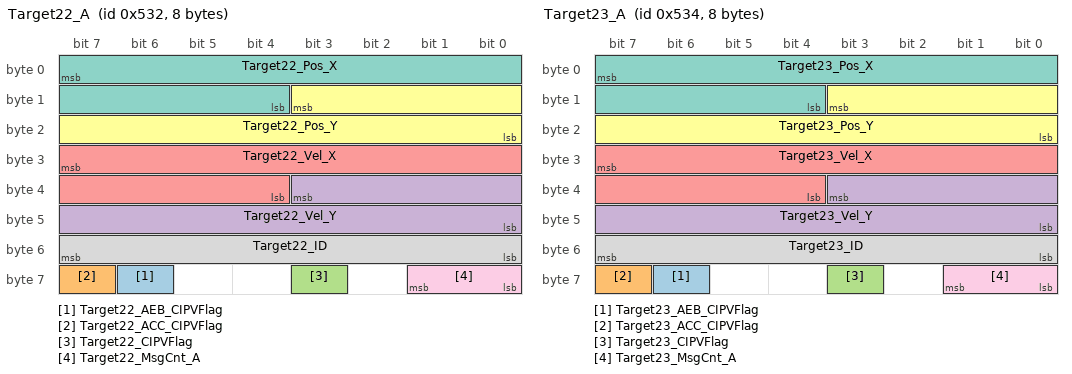
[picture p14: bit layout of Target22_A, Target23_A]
BO_ 1330 Target22_A: 8 Vector__XXX
 SG_ Target22_AEB_CIPVFlag : 62|1@0+ (1,0) [0|1] "" Vector__XXX
 SG_ Target22_ACC_CIPVFlag : 63|1@0+ (1,0) [0|1] "" Vector__XXX
 SG_ Target22_CIPVFlag : 59|1@0+ (1,0) [0|1] "" Vector__XXX
 SG_ Target22_Vel_Y : 35|12@0+ (0.05,-102) [-102|102] "m/s" Vector__XXX
 SG_ Target22_Vel_X : 31|12@0+ (0.05,-102) [-102|102] "m/s" Vector__XXX
 SG_ Target22_Pos_Y : 11|12@0+ (0.125,-128) [-128|127] "m" Vector__XXX
 SG_ Target22_Pos_X : 7|12@0+ (0.125,0) [0|255] "m" Vector__XXX
 SG_ Target22_ID : 55|8@0+ (1,0) [0|255] "" Vector__XXX
 SG_ Target22_MsgCnt_A : 57|2@0+ (1,0) [0|3] "" Vector__XXX

BO_ 1331 Target22_B: 8 Vector__XXX
 SG_ Target22_Type : 63|6@0+ (1,0) [0|4] "" Vector__XXX
 SG_ Target22_ProbExist : 49|2@0+ (1,0) [0|3] "" Vector__XXX
 SG_ Target22_DynProp : 26|3@0+ (1,0) [0|6] "" Vector__XXX
 SG_ Target22_MeasStat : 31|3@0+ (1,0) [0|4] "" Vector__XXX
 SG_ Target22_Accel_X : 7|12@0+ (0.04,-40) [-40|40] "m/s2" Vector__XXX
 SG_ Target22_ID : 23|8@0+ (1,0) [0|255] "" Vector__XXX
 SG_ Target22_MsgCnt_B : 57|2@0+ (1,0) [0|3] "" Vector__XXX

BO_ 1332 Target23_A: 8 Vector__XXX
 SG_ Target23_AEB_CIPVFlag : 62|1@0+ (1,0) [0|1] "" Vector__XXX
 SG_ Target23_ACC_CIPVFlag : 63|1@0+ (1,0) [0|1] "" Vector__XXX
 SG_ Target23_CIPVFlag : 59|1@0+ (1,0) [0|1] "" Vector__XXX
 SG_ Target23_Vel_Y : 35|12@0+ (0.05,-102) [-102|102] "m/s" Vector__XXX
 SG_ Target23_Vel_X : 31|12@0+ (0.05,-102) [-102|102] "m/s" Vector__XXX
 SG_ Target23_Pos_Y : 11|12@0+ (0.125,-128) [-128|127] "m" Vector__XXX
 SG_ Target23_Pos_X : 7|12@0+ (0.125,0) [0|255] "m" Vector__XXX
 SG_ Target23_ID : 55|8@0+ (1,0) [0|255] "" Vector__XXX
 SG_ Target23_MsgCnt_A : 57|2@0+ (1,0) [0|3] "" Vector__XXX

BO_ 1333 Target23_B: 8 Vector__XXX
 SG_ Target23_Type : 63|6@0+ (1,0) [0|4] "" Vector__XXX
 SG_ Target23_ProbExist : 49|2@0+ (1,0) [0|3] "" Vector__XXX
 SG_ Target23_DynProp : 26|3@0+ (1,0) [0|6] "" Vector__XXX
 SG_ Target23_MeasStat : 31|3@0+ (1,0) [0|4] "" Vector__XXX
 SG_ Target23_Accel_X : 7|12@0+ (0.04,-40) [-40|40] "m/s2" Vector__XXX
 SG_ Target23_ID : 23|8@0+ (1,0) [0|255] "" Vector__XXX
 SG_ Target23_MsgCnt_B : 57|2@0+ (1,0) [0|3] "" Vector__XXX

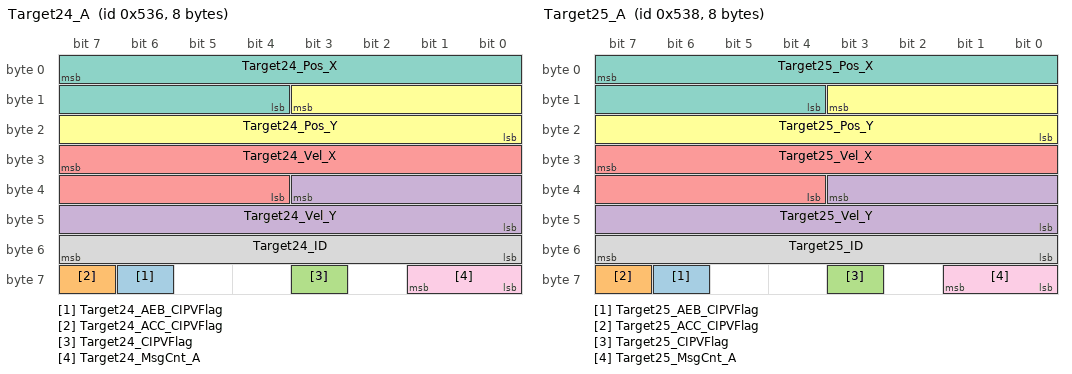
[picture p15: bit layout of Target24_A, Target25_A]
BO_ 1334 Target24_A: 8 Vector__XXX
 SG_ Target24_AEB_CIPVFlag : 62|1@0+ (1,0) [0|1] "" Vector__XXX
 SG_ Target24_ACC_CIPVFlag : 63|1@0+ (1,0) [0|1] "" Vector__XXX
 SG_ Target24_CIPVFlag : 59|1@0+ (1,0) [0|1] "" Vector__XXX
 SG_ Target24_Vel_Y : 35|12@0+ (0.05,-102) [-102|102] "m/s" Vector__XXX
 SG_ Target24_Vel_X : 31|12@0+ (0.05,-102) [-102|102] "m/s" Vector__XXX
 SG_ Target24_Pos_Y : 11|12@0+ (0.125,-128) [-128|127] "m" Vector__XXX
 SG_ Target24_Pos_X : 7|12@0+ (0.125,0) [0|255] "m" Vector__XXX
 SG_ Target24_ID : 55|8@0+ (1,0) [0|255] "" Vector__XXX
 SG_ Target24_MsgCnt_A : 57|2@0+ (1,0) [0|3] "" Vector__XXX

BO_ 1335 Target24_B: 8 Vector__XXX
 SG_ Target24_Type : 63|6@0+ (1,0) [0|4] "" Vector__XXX
 SG_ Target24_ProbExist : 49|2@0+ (1,0) [0|3] "" Vector__XXX
 SG_ Target24_DynProp : 26|3@0+ (1,0) [0|6] "" Vector__XXX
 SG_ Target24_MeasStat : 31|3@0+ (1,0) [0|4] "" Vector__XXX
 SG_ Target24_Accel_X : 7|12@0+ (0.04,-40) [-40|40] "m/s2" Vector__XXX
 SG_ Target24_ID : 23|8@0+ (1,0) [0|255] "" Vector__XXX
 SG_ Target24_MsgCnt_B : 57|2@0+ (1,0) [0|3] "" Vector__XXX

BO_ 1336 Target25_A: 8 Vector__XXX
 SG_ Target25_AEB_CIPVFlag : 62|1@0+ (1,0) [0|1] "" Vector__XXX
 SG_ Target25_ACC_CIPVFlag : 63|1@0+ (1,0) [0|1] "" Vector__XXX
 SG_ Target25_CIPVFlag : 59|1@0+ (1,0) [0|1] "" Vector__XXX
 SG_ Target25_Vel_Y : 35|12@0+ (0.05,-102) [-102|102] "m/s" Vector__XXX
 SG_ Target25_Vel_X : 31|12@0+ (0.05,-102) [-102|102] "m/s" Vector__XXX
 SG_ Target25_Pos_Y : 11|12@0+ (0.125,-128) [-128|127] "m" Vector__XXX
 SG_ Target25_Pos_X : 7|12@0+ (0.125,0) [0|255] "m" Vector__XXX
 SG_ Target25_ID : 55|8@0+ (1,0) [0|255] "" Vector__XXX
 SG_ Target25_MsgCnt_A : 57|2@0+ (1,0) [0|3] "" Vector__XXX

BO_ 1337 Target25_B: 8 Vector__XXX
 SG_ Target25_Type : 63|6@0+ (1,0) [0|4] "" Vector__XXX
 SG_ Target25_ProbExist : 49|2@0+ (1,0) [0|3] "" Vector__XXX
 SG_ Target25_DynProp : 26|3@0+ (1,0) [0|6] "" Vector__XXX
 SG_ Target25_MeasStat : 31|3@0+ (1,0) [0|4] "" Vector__XXX
 SG_ Target25_Accel_X : 7|12@0+ (0.04,-40) [-40|40] "m/s2" Vector__XXX
 SG_ Target25_ID : 23|8@0+ (1,0) [0|255] "" Vector__XXX
 SG_ Target25_MsgCnt_B : 57|2@0+ (1,0) [0|3] "" Vector__XXX

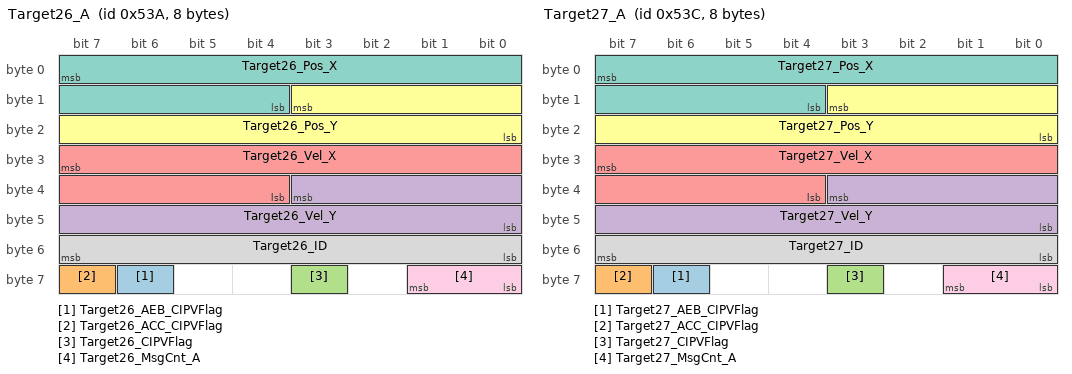
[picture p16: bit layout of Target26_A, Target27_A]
BO_ 1338 Target26_A: 8 Vector__XXX
 SG_ Target26_AEB_CIPVFlag : 62|1@0+ (1,0) [0|1] "" Vector__XXX
 SG_ Target26_ACC_CIPVFlag : 63|1@0+ (1,0) [0|1] "" Vector__XXX
 SG_ Target26_CIPVFlag : 59|1@0+ (1,0) [0|1] "" Vector__XXX
 SG_ Target26_Vel_Y : 35|12@0+ (0.05,-102) [-102|102] "m/s" Vector__XXX
 SG_ Target26_Vel_X : 31|12@0+ (0.05,-102) [-102|102] "m/s" Vector__XXX
 SG_ Target26_Pos_Y : 11|12@0+ (0.125,-128) [-128|127] "m" Vector__XXX
 SG_ Target26_Pos_X : 7|12@0+ (0.125,0) [0|255] "m" Vector__XXX
 SG_ Target26_ID : 55|8@0+ (1,0) [0|255] "" Vector__XXX
 SG_ Target26_MsgCnt_A : 57|2@0+ (1,0) [0|3] "" Vector__XXX

BO_ 1339 Target26_B: 8 Vector__XXX
 SG_ Target26_Type : 63|6@0+ (1,0) [0|4] "" Vector__XXX
 SG_ Target26_ProbExist : 49|2@0+ (1,0) [0|3] "" Vector__XXX
 SG_ Target26_DynProp : 26|3@0+ (1,0) [0|6] "" Vector__XXX
 SG_ Target26_MeasStat : 31|3@0+ (1,0) [0|4] "" Vector__XXX
 SG_ Target26_Accel_X : 7|12@0+ (0.04,-40) [-40|40] "m/s2" Vector__XXX
 SG_ Target26_ID : 23|8@0+ (1,0) [0|255] "" Vector__XXX
 SG_ Target26_MsgCnt_B : 57|2@0+ (1,0) [0|3] "" Vector__XXX

BO_ 1340 Target27_A: 8 Vector__XXX
 SG_ Target27_AEB_CIPVFlag : 62|1@0+ (1,0) [0|1] "" Vector__XXX
 SG_ Target27_ACC_CIPVFlag : 63|1@0+ (1,0) [0|1] "" Vector__XXX
 SG_ Target27_CIPVFlag : 59|1@0+ (1,0) [0|1] "" Vector__XXX
 SG_ Target27_Vel_Y : 35|12@0+ (0.05,-102) [-102|102] "m/s" Vector__XXX
 SG_ Target27_Vel_X : 31|12@0+ (0.05,-102) [-102|102] "m/s" Vector__XXX
 SG_ Target27_Pos_Y : 11|12@0+ (0.125,-128) [-128|127] "m" Vector__XXX
 SG_ Target27_Pos_X : 7|12@0+ (0.125,0) [0|255] "m" Vector__XXX
 SG_ Target27_ID : 55|8@0+ (1,0) [0|255] "" Vector__XXX
 SG_ Target27_MsgCnt_A : 57|2@0+ (1,0) [0|3] "" Vector__XXX

BO_ 1341 Target27_B: 8 Vector__XXX
 SG_ Target27_Type : 63|6@0+ (1,0) [0|4] "" Vector__XXX
 SG_ Target27_ProbExist : 49|2@0+ (1,0) [0|3] "" Vector__XXX
 SG_ Target27_DynProp : 26|3@0+ (1,0) [0|6] "" Vector__XXX
 SG_ Target27_MeasStat : 31|3@0+ (1,0) [0|4] "" Vector__XXX
 SG_ Target27_Accel_X : 7|12@0+ (0.04,-40) [-40|40] "m/s2" Vector__XXX
 SG_ Target27_ID : 23|8@0+ (1,0) [0|255] "" Vector__XXX
 SG_ Target27_MsgCnt_B : 57|2@0+ (1,0) [0|3] "" Vector__XXX

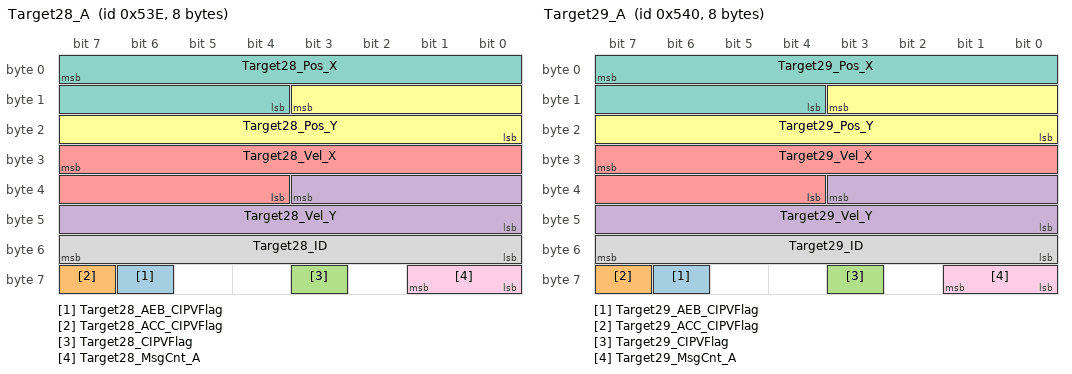
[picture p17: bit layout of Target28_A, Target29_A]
BO_ 1342 Target28_A: 8 Vector__XXX
 SG_ Target28_AEB_CIPVFlag : 62|1@0+ (1,0) [0|1] "" Vector__XXX
 SG_ Target28_ACC_CIPVFlag : 63|1@0+ (1,0) [0|1] "" Vector__XXX
 SG_ Target28_CIPVFlag : 59|1@0+ (1,0) [0|1] "" Vector__XXX
 SG_ Target28_Vel_Y : 35|12@0+ (0.05,-102) [-102|102] "m/s" Vector__XXX
 SG_ Target28_Vel_X : 31|12@0+ (0.05,-102) [-102|102] "m/s" Vector__XXX
 SG_ Target28_Pos_Y : 11|12@0+ (0.125,-128) [-128|127] "m" Vector__XXX
 SG_ Target28_Pos_X : 7|12@0+ (0.125,0) [0|255] "m" Vector__XXX
 SG_ Target28_ID : 55|8@0+ (1,0) [0|255] "" Vector__XXX
 SG_ Target28_MsgCnt_A : 57|2@0+ (1,0) [0|3] "" Vector__XXX

BO_ 1343 Target28_B: 8 Vector__XXX
 SG_ Target28_Type : 63|6@0+ (1,0) [0|4] "" Vector__XXX
 SG_ Target28_ProbExist : 49|2@0+ (1,0) [0|3] "" Vector__XXX
 SG_ Target28_DynProp : 26|3@0+ (1,0) [0|6] "" Vector__XXX
 SG_ Target28_MeasStat : 31|3@0+ (1,0) [0|4] "" Vector__XXX
 SG_ Target28_Accel_X : 7|12@0+ (0.04,-40) [-40|40] "m/s2" Vector__XXX
 SG_ Target28_ID : 23|8@0+ (1,0) [0|255] "" Vector__XXX
 SG_ Target28_MsgCnt_B : 57|2@0+ (1,0) [0|3] "" Vector__XXX

BO_ 1344 Target29_A: 8 Vector__XXX
 SG_ Target29_AEB_CIPVFlag : 62|1@0+ (1,0) [0|1] "" Vector__XXX
 SG_ Target29_ACC_CIPVFlag : 63|1@0+ (1,0) [0|1] "" Vector__XXX
 SG_ Target29_CIPVFlag : 59|1@0+ (1,0) [0|1] "" Vector__XXX
 SG_ Target29_Vel_Y : 35|12@0+ (0.05,-102) [-102|102] "m/s" Vector__XXX
 SG_ Target29_Vel_X : 31|12@0+ (0.05,-102) [-102|102] "m/s" Vector__XXX
 SG_ Target29_Pos_Y : 11|12@0+ (0.125,-128) [-128|127] "m" Vector__XXX
 SG_ Target29_Pos_X : 7|12@0+ (0.125,0) [0|255] "m" Vector__XXX
 SG_ Target29_ID : 55|8@0+ (1,0) [0|255] "" Vector__XXX
 SG_ Target29_MsgCnt_A : 57|2@0+ (1,0) [0|3] "" Vector__XXX

BO_ 1345 Target29_B: 8 Vector__XXX
 SG_ Target29_Type : 63|6@0+ (1,0) [0|4] "" Vector__XXX
 SG_ Target29_ProbExist : 49|2@0+ (1,0) [0|3] "" Vector__XXX
 SG_ Target29_DynProp : 26|3@0+ (1,0) [0|6] "" Vector__XXX
 SG_ Target29_MeasStat : 31|3@0+ (1,0) [0|4] "" Vector__XXX
 SG_ Target29_Accel_X : 7|12@0+ (0.04,-40) [-40|40] "m/s2" Vector__XXX
 SG_ Target29_ID : 23|8@0+ (1,0) [0|255] "" Vector__XXX
 SG_ Target29_MsgCnt_B : 57|2@0+ (1,0) [0|3] "" Vector__XXX

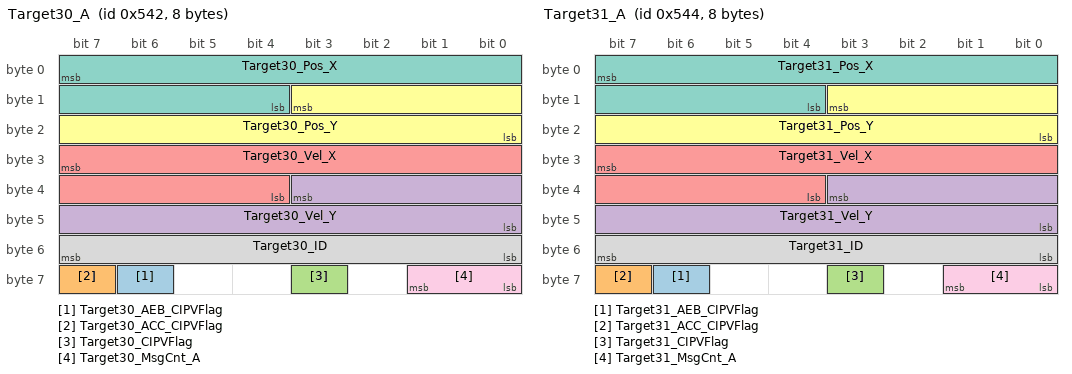
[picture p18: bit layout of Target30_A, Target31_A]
BO_ 1346 Target30_A: 8 Vector__XXX
 SG_ Target30_AEB_CIPVFlag : 62|1@0+ (1,0) [0|1] "" Vector__XXX
 SG_ Target30_ACC_CIPVFlag : 63|1@0+ (1,0) [0|1] "" Vector__XXX
 SG_ Target30_CIPVFlag : 59|1@0+ (1,0) [0|1] "" Vector__XXX
 SG_ Target30_Vel_Y : 35|12@0+ (0.05,-102) [-102|102] "m/s" Vector__XXX
 SG_ Target30_Vel_X : 31|12@0+ (0.05,-102) [-102|102] "m/s" Vector__XXX
 SG_ Target30_Pos_Y : 11|12@0+ (0.125,-128) [-128|127] "m" Vector__XXX
 SG_ Target30_Pos_X : 7|12@0+ (0.125,0) [0|255] "m" Vector__XXX
 SG_ Target30_ID : 55|8@0+ (1,0) [0|255] "" Vector__XXX
 SG_ Target30_MsgCnt_A : 57|2@0+ (1,0) [0|3] "" Vector__XXX

BO_ 1347 Target30_B: 8 Vector__XXX
 SG_ Target30_Type : 63|6@0+ (1,0) [0|4] "" Vector__XXX
 SG_ Target30_ProbExist : 49|2@0+ (1,0) [0|3] "" Vector__XXX
 SG_ Target30_DynProp : 26|3@0+ (1,0) [0|6] "" Vector__XXX
 SG_ Target30_MeasStat : 31|3@0+ (1,0) [0|4] "" Vector__XXX
 SG_ Target30_Accel_X : 7|12@0+ (0.04,-40) [-40|40] "m/s2" Vector__XXX
 SG_ Target30_ID : 23|8@0+ (1,0) [0|255] "" Vector__XXX
 SG_ Target30_MsgCnt_B : 57|2@0+ (1,0) [0|3] "" Vector__XXX

BO_ 1348 Target31_A: 8 Vector__XXX
 SG_ Target31_AEB_CIPVFlag : 62|1@0+ (1,0) [0|1] "" Vector__XXX
 SG_ Target31_ACC_CIPVFlag : 63|1@0+ (1,0) [0|1] "" Vector__XXX
 SG_ Target31_CIPVFlag : 59|1@0+ (1,0) [0|1] "" Vector__XXX
 SG_ Target31_Vel_Y : 35|12@0+ (0.05,-102) [-102|102] "m/s" Vector__XXX
 SG_ Target31_Vel_X : 31|12@0+ (0.05,-102) [-102|102] "m/s" Vector__XXX
 SG_ Target31_Pos_Y : 11|12@0+ (0.125,-128) [-128|127] "m" Vector__XXX
 SG_ Target31_Pos_X : 7|12@0+ (0.125,0) [0|255] "m" Vector__XXX
 SG_ Target31_ID : 55|8@0+ (1,0) [0|255] "" Vector__XXX
 SG_ Target31_MsgCnt_A : 57|2@0+ (1,0) [0|3] "" Vector__XXX

BO_ 1349 Target31_B: 8 Vector__XXX
 SG_ Target31_Type : 63|6@0+ (1,0) [0|4] "" Vector__XXX
 SG_ Target31_ProbExist : 49|2@0+ (1,0) [0|3] "" Vector__XXX
 SG_ Target31_DynProp : 26|3@0+ (1,0) [0|6] "" Vector__XXX
 SG_ Target31_MeasStat : 31|3@0+ (1,0) [0|4] "" Vector__XXX
 SG_ Target31_Accel_X : 7|12@0+ (0.04,-40) [-40|40] "m/s2" Vector__XXX
 SG_ Target31_ID : 23|8@0+ (1,0) [0|255] "" Vector__XXX
 SG_ Target31_MsgCnt_B : 57|2@0+ (1,0) [0|3] "" Vector__XXX

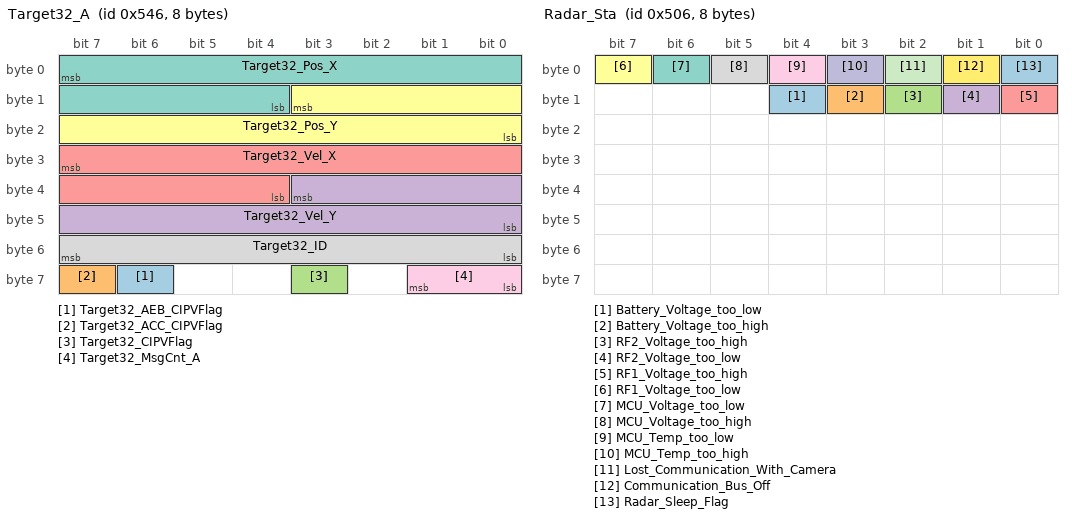
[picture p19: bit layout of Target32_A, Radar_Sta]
BO_ 1350 Target32_A: 8 Vector__XXX
 SG_ Target32_AEB_CIPVFlag : 62|1@0+ (1,0) [0|1] "" Vector__XXX
 SG_ Target32_ACC_CIPVFlag : 63|1@0+ (1,0) [0|1] "" Vector__XXX
 SG_ Target32_CIPVFlag : 59|1@0+ (1,0) [0|1] "" Vector__XXX
 SG_ Target32_Vel_Y : 35|12@0+ (0.05,-102) [-102|102] "m/s" Vector__XXX
 SG_ Target32_Vel_X : 31|12@0+ (0.05,-102) [-102|102] "m/s" Vector__XXX
 SG_ Target32_Pos_Y : 11|12@0+ (0.125,-128) [-128|127] "m" Vector__XXX
 SG_ Target32_Pos_X : 7|12@0+ (0.125,0) [0|255] "m" Vector__XXX
 SG_ Target32_ID : 55|8@0+ (1,0) [0|255] "" Vector__XXX
 SG_ Target32_MsgCnt_A : 57|2@0+ (1,0) [0|3] "" Vector__XXX

BO_ 1351 Target32_B: 8 Vector__XXX
 SG_ Target32_Type : 63|6@0+ (1,0) [0|4] "" Vector__XXX
 SG_ Target32_ProbExist : 49|2@0+ (1,0) [0|3] "" Vector__XXX
 SG_ Target32_DynProp : 26|3@0+ (1,0) [0|6] "" Vector__XXX
 SG_ Target32_MeasStat : 31|3@0+ (1,0) [0|4] "" Vector__XXX
 SG_ Target32_Accel_X : 7|12@0+ (0.04,-40) [-40|40] "m/s2" Vector__XXX
 SG_ Target32_ID : 23|8@0+ (1,0) [0|255] "" Vector__XXX
 SG_ Target32_MsgCnt_B : 57|2@0+ (1,0) [0|3] "" Vector__XXX

BO_ 1286 Radar_Sta: 8 Vector__XXX
 SG_ Battery_Voltage_too_low : 12|1@0+ (1,0) [0|1] "" Vector__XXX
 SG_ Battery_Voltage_too_high : 11|1@0+ (1,0) [0|1] "" Vector__XXX
 SG_ RF2_Voltage_too_high : 10|1@0+ (1,0) [0|1] "" Vector__XXX
 SG_ RF2_Voltage_too_low : 9|1@0+ (1,0) [0|1] "" Vector__XXX
 SG_ RF1_Voltage_too_high : 8|1@0+ (1,0) [0|1] "" Vector__XXX
 SG_ RF1_Voltage_too_low : 7|1@0+ (1,0) [0|1] "" Vector__XXX
 SG_ MCU_Voltage_too_low : 6|1@1+ (1,0) [0|1] "" Vector__XXX
 SG_ MCU_Voltage_too_high : 5|1@0+ (1,0) [0|1] "" Vector__XXX
 SG_ MCU_Temp_too_low : 4|1@0+ (1,0) [0|1] "" Vector__XXX
 SG_ MCU_Temp_too_high : 3|1@0+ (1,0) [0|1] "" Vector__XXX
 SG_ Lost_Communication_With_Camera : 2|1@0+ (1,0) [0|1] "" Vector__XXX
 SG_ Communication_Bus_Off : 1|1@0+ (1,0) [0|1] "" Vector__XXX
 SG_ Radar_Sleep_Flag : 0|1@0+ (1,0) [0|1] "" Vector__XXX

BO_ 1285 Header: 8 Vector__XXX
 SG_ Radar_Frame : 47|16@0+ (1,0) [0|65535] "" Vector__XXX
 SG_ Func_Status : 15|8@0+ (1,0) [0|255] "" Vector__XXX
 SG_ AEB_CIPV_ID : 39|8@0+ (1,0) [0|255] "" Vector__XXX
 SG_ ACC_CIPV_ID : 31|8@0+ (1,0) [0|255] "" Vector__XXX
 SG_ CIPV_ID : 23|8@0+ (1,0) [0|255] "" Vector__XXX
 SG_ TunnelFlag : 0|1@0+ (1,0) [0|1] "" Vector__XXX
 SG_ No_Obj : 7|6@0+ (1,0) [0|32] "" Vector__XXX

VAL_ 1289 Target1_Type 4 "Truck" 3 "Car" 2 "Bike" 1 "Pedestrian" 0 "Unknown" ;
VAL_ 1289 Target1_ProbExist 3 "99%" 2 "75%" 1 "50%" 0 "25%" ;
VAL_ 1289 Target1_DynProp 6 "Ditchcover" 5 "Flyover" 4 "Oncoming" 3 "Moving" 2 "Stopped" 1 "Standing" 0 "Unclassified" ;
VAL_ 1289 Target1_MeasStat 4 "Invalid" 3 "Measured Object" 2 "Predicted Object" 1 "New Object" 0 "No object" ;
VAL_ 1291 Target2_Type 4 "Truck" 3 "Car" 2 "Bike" 1 "Pedestrian" 0 "Unknown" ;
VAL_ 1291 Target2_ProbExist 3 "99%" 2 "75%" 1 "50%" 0 "25%" ;
VAL_ 1291 Target2_DynProp 6 "Ditchcover" 5 "Flyover" 4 "Oncoming" 3 "Moving" 2 "Stopped" 1 "Standing" 0 "Unclassified" ;
VAL_ 1291 Target2_MeasStat 4 "Invalid" 3 "Measured Object" 2 "Predicted Object" 1 "New Object" 0 "No object" ;
VAL_ 1293 Target3_Type 4 "Truck" 3 "Car" 2 "Bike" 1 "Pedestrian" 0 "Unknown" ;
VAL_ 1293 Target3_ProbExist 3 "99%" 2 "75%" 1 "50%" 0 "25%" ;
VAL_ 1293 Target3_DynProp 6 "Ditchcover" 5 "Flyover" 4 "Oncoming" 3 "Moving" 2 "Stopped" 1 "Standing" 0 "Unclassified" ;
VAL_ 1293 Target3_MeasStat 4 "Invalid" 3 "Measured Object" 2 "Predicted Object" 1 "New Object" 0 "No object" ;
VAL_ 1295 Target4_Type 4 "Truck" 3 "Car" 2 "Bike" 1 "Pedestrian" 0 "Unknown" ;
VAL_ 1295 Target4_ProbExist 3 "99%" 2 "75%" 1 "50%" 0 "25%" ;
VAL_ 1295 Target4_DynProp 6 "Ditchcover" 5 "Flyover" 4 "Oncoming" 3 "Moving" 2 "Stopped" 1 "Standing" 0 "Unclassified" ;
VAL_ 1295 Target4_MeasStat 4 "Invalid" 3 "Measured Object" 2 "Predicted Object" 1 "New Object" 0 "No object" ;
VAL_ 1297 Target5_Type 4 "Truck" 3 "Car" 2 "Bike" 1 "Pedestrian" 0 "Unknown" ;
VAL_ 1297 Target5_ProbExist 3 "99%" 2 "75%" 1 "50%" 0 "25%" ;
VAL_ 1297 Target5_DynProp 6 "Ditchcover" 5 "Flyover" 4 "Oncoming" 3 "Moving" 2 "Stopped" 1 "Standing" 0 "Unclassified" ;
VAL_ 1297 Target5_MeasStat 4 "Invalid" 3 "Measured Object" 2 "Predicted Object" 1 "New Object" 0 "No object" ;
VAL_ 1299 Target6_Type 4 "Truck" 3 "Car" 2 "Bike" 1 "Pedestrian" 0 "Unknown" ;
VAL_ 1299 Target6_ProbExist 3 "99%" 2 "75%" 1 "50%" 0 "25%" ;
VAL_ 1299 Target6_DynProp 6 "Ditchcover" 5 "Flyover" 4 "Oncoming" 3 "Moving" 2 "Stopped" 1 "Standing" 0 "Unclassified" ;
VAL_ 1299 Target6_MeasStat 4 "Invalid" 3 "Measured Object" 2 "Predicted Object" 1 "New Object" 0 "No object" ;
VAL_ 1301 Target7_Type 4 "Truck" 3 "Car" 2 "Bike" 1 "Pedestrian" 0 "Unknown" ;
VAL_ 1301 Target7_ProbExist 3 "99%" 2 "75%" 1 "50%" 0 "25%" ;
VAL_ 1301 Target7_DynProp 6 "Ditchcover" 5 "Flyover" 4 "Oncoming" 3 "Moving" 2 "Stopped" 1 "Standing" 0 "Unclassified" ;
VAL_ 1301 Target7_MeasStat 4 "Invalid" 3 "Measured Object" 2 "Predicted Object" 1 "New Object" 0 "No object" ;
VAL_ 1303 Target8_Type 4 "Truck" 3 "Car" 2 "Bike" 1 "Pedestrian" 0 "Unknown" ;
VAL_ 1303 Target8_ProbExist 3 "99%" 2 "75%" 1 "50%" 0 "25%" ;
VAL_ 1303 Target8_DynProp 6 "Ditchcover" 5 "Flyover" 4 "Oncoming" 3 "Moving" 2 "Stopped" 1 "Standing" 0 "Unclassified" ;
VAL_ 1303 Target8_MeasStat 4 "Invalid" 3 "Measured Object" 2 "Predicted Object" 1 "New Object" 0 "No object" ;
VAL_ 1305 Target9_Type 4 "Truck" 3 "Car" 2 "Bike" 1 "Pedestrian" 0 "Unknown" ;
VAL_ 1305 Target9_ProbExist 3 "99%" 2 "75%" 1 "50%" 0 "25%" ;
VAL_ 1305 Target9_DynProp 6 "Ditchcover" 5 "Flyover" 4 "Oncoming" 3 "Moving" 2 "Stopped" 1 "Standing" 0 "Unclassified" ;
VAL_ 1305 Target9_MeasStat 4 "Invalid" 3 "Measured Object" 2 "Predicted Object" 1 "New Object" 0 "No object" ;
VAL_ 1307 Target10_Type 4 "Truck" 3 "Car" 2 "Bike" 1 "Pedestrian" 0 "Unknown" ;
VAL_ 1307 Target10_ProbExist 3 "99%" 2 "75%" 1 "50%" 0 "25%" ;
VAL_ 1307 Target10_DynProp 6 "Ditchcover" 5 "Flyover" 4 "Oncoming" 3 "Moving" 2 "Stopped" 1 "Standing" 0 "Unclassified" ;
VAL_ 1307 Target10_MeasStat 4 "Invalid" 3 "Measured Object" 2 "Predicted Object" 1 "New Object" 0 "No object" ;
VAL_ 1309 Target11_Type 4 "Truck" 3 "Car" 2 "Bike" 1 "Pedestrian" 0 "Unknown" ;
VAL_ 1309 Target11_ProbExist 3 "99%" 2 "75%" 1 "50%" 0 "25%" ;
VAL_ 1309 Target11_DynProp 6 "Ditchcover" 5 "Flyover" 4 "Oncoming" 3 "Moving" 2 "Stopped" 1 "Standing" 0 "Unclassified" ;
VAL_ 1309 Target11_MeasStat 4 "Invalid" 3 "Measured Object" 2 "Predicted Object" 1 "New Object" 0 "No object" ;
VAL_ 1311 Target12_Type 4 "Truck" 3 "Car" 2 "Bike" 1 "Pedestrian" 0 "Unknown" ;
VAL_ 1311 Target12_ProbExist 3 "99%" 2 "75%" 1 "50%" 0 "25%" ;
VAL_ 1311 Target12_DynProp 6 "Ditchcover" 5 "Flyover" 4 "Oncoming" 3 "Moving" 2 "Stopped" 1 "Standing" 0 "Unclassified" ;
VAL_ 1311 Target12_MeasStat 4 "Invalid" 3 "Measured Object" 2 "Predicted Object" 1 "New Object" 0 "No object" ;
VAL_ 1313 Target13_Type 4 "Truck" 3 "Car" 2 "Bike" 1 "Pedestrian" 0 "Unknown" ;
VAL_ 1313 Target13_ProbExist 3 "99%" 2 "75%" 1 "50%" 0 "25%" ;
VAL_ 1313 Target13_DynProp 6 "Ditchcover" 5 "Flyover" 4 "Oncoming" 3 "Moving" 2 "Stopped" 1 "Standing" 0 "Unclassified" ;
VAL_ 1313 Target13_MeasStat 4 "Invalid" 3 "Measured Object" 2 "Predicted Object" 1 "New Object" 0 "No object" ;
VAL_ 1315 Target14_Type 4 "Truck" 3 "Car" 2 "Bike" 1 "Pedestrian" 0 "Unknown" ;
VAL_ 1315 Target14_ProbExist 3 "99%" 2 "75%" 1 "50%" 0 "25%" ;
VAL_ 1315 Target14_DynProp 6 "Ditchcover" 5 "Flyover" 4 "Oncoming" 3 "Moving" 2 "Stopped" 1 "Standing" 0 "Unclassified" ;
VAL_ 1315 Target14_MeasStat 4 "Invalid" 3 "Measured Object" 2 "Predicted Object" 1 "New Object" 0 "No object" ;
VAL_ 1317 Target15_Type 4 "Truck" 3 "Car" 2 "Bike" 1 "Pedestrian" 0 "Unknown" ;
VAL_ 1317 Target15_ProbExist 3 "99%" 2 "75%" 1 "50%" 0 "25%" ;
VAL_ 1317 Target15_DynProp 6 "Ditchcover" 5 "Flyover" 4 "Oncoming" 3 "Moving" 2 "Stopped" 1 "Standing" 0 "Unclassified" ;
VAL_ 1317 Target15_MeasStat 4 "Invalid" 3 "Measured Object" 2 "Predicted Object" 1 "New Object" 0 "No object" ;
VAL_ 1319 Target16_Type 4 "Truck" 3 "Car" 2 "Bike" 1 "Pedestrian" 0 "Unknown" ;
VAL_ 1319 Target16_ProbExist 3 "99%" 2 "75%" 1 "50%" 0 "25%" ;
VAL_ 1319 Target16_DynProp 6 "Ditchcover" 5 "Flyover" 4 "Oncoming" 3 "Moving" 2 "Stopped" 1 "Standing" 0 "Unclassified" ;
VAL_ 1319 Target16_MeasStat 4 "Invalid" 3 "Measured Object" 2 "Predicted Object" 1 "New Object" 0 "No object" ;
VAL_ 1321 Target17_Type 4 "Truck" 3 "Car" 2 "Bike" 1 "Pedestrian" 0 "Unknown" ;
VAL_ 1321 Target17_ProbExist 3 "99%" 2 "75%" 1 "50%" 0 "25%" ;
VAL_ 1321 Target17_DynProp 6 "Ditchcover" 5 "Flyover" 4 "Oncoming" 3 "Moving" 2 "Stopped" 1 "Standing" 0 "Unclassified" ;
VAL_ 1321 Target17_MeasStat 4 "Invalid" 3 "Measured Object" 2 "Predicted Object" 1 "New Object" 0 "No object" ;
VAL_ 1323 Target18_Type 4 "Truck" 3 "Car" 2 "Bike" 1 "Pedestrian" 0 "Unknown" ;
VAL_ 1323 Target18_ProbExist 3 "99%" 2 "75%" 1 "50%" 0 "25%" ;
VAL_ 1323 Target18_DynProp 6 "Ditchcover" 5 "Flyover" 4 "Oncoming" 3 "Moving" 2 "Stopped" 1 "Standing" 0 "Unclassified" ;
VAL_ 1323 Target18_MeasStat 4 "Invalid" 3 "Measured Object" 2 "Predicted Object" 1 "New Object" 0 "No object" ;
VAL_ 1325 Target19_Type 4 "Truck" 3 "Car" 2 "Bike" 1 "Pedestrian" 0 "Unknown" ;
VAL_ 1325 Target19_ProbExist 3 "99%" 2 "75%" 1 "50%" 0 "25%" ;
VAL_ 1325 Target19_DynProp 6 "Ditchcover" 5 "Flyover" 4 "Oncoming" 3 "Moving" 2 "Stopped" 1 "Standing" 0 "Unclassified" ;
VAL_ 1325 Target19_MeasStat 4 "Invalid" 3 "Measured Object" 2 "Predicted Object" 1 "New Object" 0 "No object" ;
VAL_ 1327 Target20_Type 4 "Truck" 3 "Car" 2 "Bike" 1 "Pedestrian" 0 "Unknown" ;
VAL_ 1327 Target20_ProbExist 3 "99%" 2 "75%" 1 "50%" 0 "25%" ;
VAL_ 1327 Target20_DynProp 6 "Ditchcover" 5 "Flyover" 4 "Oncoming" 3 "Moving" 2 "Stopped" 1 "Standing" 0 "Unclassified" ;
VAL_ 1327 Target20_MeasStat 4 "Invalid" 3 "Measured Object" 2 "Predicted Object" 1 "New Object" 0 "No object" ;
VAL_ 1329 Target21_Type 4 "Truck" 3 "Car" 2 "Bike" 1 "Pedestrian" 0 "Unknown" ;
VAL_ 1329 Target21_ProbExist 3 "99%" 2 "75%" 1 "50%" 0 "25%" ;
VAL_ 1329 Target21_DynProp 6 "Ditchcover" 5 "Flyover" 4 "Oncoming" 3 "Moving" 2 "Stopped" 1 "Standing" 0 "Unclassified" ;
VAL_ 1329 Target21_MeasStat 4 "Invalid" 3 "Measured Object" 2 "Predicted Object" 1 "New Object" 0 "No object" ;
VAL_ 1331 Target22_Type 4 "Truck" 3 "Car" 2 "Bike" 1 "Pedestrian" 0 "Unknown" ;
VAL_ 1331 Target22_ProbExist 3 "99%" 2 "75%" 1 "50%" 0 "25%" ;
VAL_ 1331 Target22_DynProp 6 "Ditchcover" 5 "Flyover" 4 "Oncoming" 3 "Moving" 2 "Stopped" 1 "Standing" 0 "Unclassified" ;
VAL_ 1331 Target22_MeasStat 4 "Invalid" 3 "Measured Object" 2 "Predicted Object" 1 "New Object" 0 "No object" ;
VAL_ 1333 Target23_Type 4 "Truck" 3 "Car" 2 "Bike" 1 "Pedestrian" 0 "Unknown" ;
VAL_ 1333 Target23_ProbExist 3 "99%" 2 "75%" 1 "50%" 0 "25%" ;
VAL_ 1333 Target23_DynProp 6 "Ditchcover" 5 "Flyover" 4 "Oncoming" 3 "Moving" 2 "Stopped" 1 "Standing" 0 "Unclassified" ;
VAL_ 1333 Target23_MeasStat 4 "Invalid" 3 "Measured Object" 2 "Predicted Object" 1 "New Object" 0 "No object" ;
VAL_ 1335 Target24_Type 4 "Truck" 3 "Car" 2 "Bike" 1 "Pedestrian" 0 "Unknown" ;
VAL_ 1335 Target24_ProbExist 3 "99%" 2 "75%" 1 "50%" 0 "25%" ;
VAL_ 1335 Target24_DynProp 6 "Ditchcover" 5 "Flyover" 4 "Oncoming" 3 "Moving" 2 "Stopped" 1 "Standing" 0 "Unclassified" ;
VAL_ 1335 Target24_MeasStat 4 "Invalid" 3 "Measured Object" 2 "Predicted Object" 1 "New Object" 0 "No object" ;
VAL_ 1337 Target25_Type 4 "Truck" 3 "Car" 2 "Bike" 1 "Pedestrian" 0 "Unknown" ;
VAL_ 1337 Target25_ProbExist 3 "99%" 2 "75%" 1 "50%" 0 "25%" ;
VAL_ 1337 Target25_DynProp 6 "Ditchcover" 5 "Flyover" 4 "Oncoming" 3 "Moving" 2 "Stopped" 1 "Standing" 0 "Unclassified" ;
VAL_ 1337 Target25_MeasStat 4 "Invalid" 3 "Measured Object" 2 "Predicted Object" 1 "New Object" 0 "No object" ;
VAL_ 1339 Target26_Type 4 "Truck" 3 "Car" 2 "Bike" 1 "Pedestrian" 0 "Unknown" ;
VAL_ 1339 Target26_ProbExist 3 "99%" 2 "75%" 1 "50%" 0 "25%" ;
VAL_ 1339 Target26_DynProp 6 "Ditchcover" 5 "Flyover" 4 "Oncoming" 3 "Moving" 2 "Stopped" 1 "Standing" 0 "Unclassified" ;
VAL_ 1339 Target26_MeasStat 4 "Invalid" 3 "Measured Object" 2 "Predicted Object" 1 "New Object" 0 "No object" ;
VAL_ 1341 Target27_Type 4 "Truck" 3 "Car" 2 "Bike" 1 "Pedestrian" 0 "Unknown" ;
VAL_ 1341 Target27_ProbExist 3 "99%" 2 "75%" 1 "50%" 0 "25%" ;
VAL_ 1341 Target27_DynProp 6 "Ditchcover" 5 "Flyover" 4 "Oncoming" 3 "Moving" 2 "Stopped" 1 "Standing" 0 "Unclassified" ;
VAL_ 1341 Target27_MeasStat 4 "Invalid" 3 "Measured Object" 2 "Predicted Object" 1 "New Object" 0 "No object" ;
VAL_ 1343 Target28_Type 4 "Truck" 3 "Car" 2 "Bike" 1 "Pedestrian" 0 "Unknown" ;
VAL_ 1343 Target28_ProbExist 3 "99%" 2 "75%" 1 "50%" 0 "25%" ;
VAL_ 1343 Target28_DynProp 6 "Ditchcover" 5 "Flyover" 4 "Oncoming" 3 "Moving" 2 "Stopped" 1 "Standing" 0 "Unclassified" ;
VAL_ 1343 Target28_MeasStat 4 "Invalid" 3 "Measured Object" 2 "Predicted Object" 1 "New Object" 0 "No object" ;
VAL_ 1345 Target29_Type 4 "Truck" 3 "Car" 2 "Bike" 1 "Pedestrian" 0 "Unknown" ;
VAL_ 1345 Target29_ProbExist 3 "99%" 2 "75%" 1 "50%" 0 "25%" ;
VAL_ 1345 Target29_DynProp 6 "Ditchcover" 5 "Flyover" 4 "Oncoming" 3 "Moving" 2 "Stopped" 1 "Standing" 0 "Unclassified" ;
VAL_ 1345 Target29_MeasStat 4 "Invalid" 3 "Measured Object" 2 "Predicted Object" 1 "New Object" 0 "No object" ;
VAL_ 1347 Target30_Type 4 "Truck" 3 "Car" 2 "Bike" 1 "Pedestrian" 0 "Unknown" ;
VAL_ 1347 Target30_ProbExist 3 "99%" 2 "75%" 1 "50%" 0 "25%" ;
VAL_ 1347 Target30_DynProp 6 "Ditchcover" 5 "Flyover" 4 "Oncoming" 3 "Moving" 2 "Stopped" 1 "Standing" 0 "Unclassified" ;
VAL_ 1347 Target30_MeasStat 4 "Invalid" 3 "Measured Object" 2 "Predicted Object" 1 "New Object" 0 "No object" ;
VAL_ 1349 Target31_Type 4 "Truck" 3 "Car" 2 "Bike" 1 "Pedestrian" 0 "Unknown" ;
VAL_ 1349 Target31_ProbExist 3 "99%" 2 "75%" 1 "50%" 0 "25%" ;
VAL_ 1349 Target31_DynProp 6 "Ditchcover" 5 "Flyover" 4 "Oncoming" 3 "Moving" 2 "Stopped" 1 "Standing" 0 "Unclassified" ;
VAL_ 1349 Target31_MeasStat 4 "Invalid" 3 "Measured Object" 2 "Predicted Object" 1 "New Object" 0 "No object" ;
VAL_ 1351 Target32_Type 4 "Truck" 3 "Car" 2 "Bike" 1 "Pedestrian" 0 "Unknown" ;
VAL_ 1351 Target32_ProbExist 3 "99%" 2 "75%" 1 "50%" 0 "25%" ;
VAL_ 1351 Target32_DynProp 6 "Ditchcover" 5 "Flyover" 4 "Oncoming" 3 "Moving" 2 "Stopped" 1 "Standing" 0 "Unclassified" ;
VAL_ 1351 Target32_MeasStat 4 "Invalid" 3 "Measured Object" 2 "Predicted Object" 1 "New Object" 0 "No object" ;
